VERSION ""

NS_ :

BS_:

BU_: Host Node0 Node1 Node2 Node3 Node4 Node5 Node6 Node7

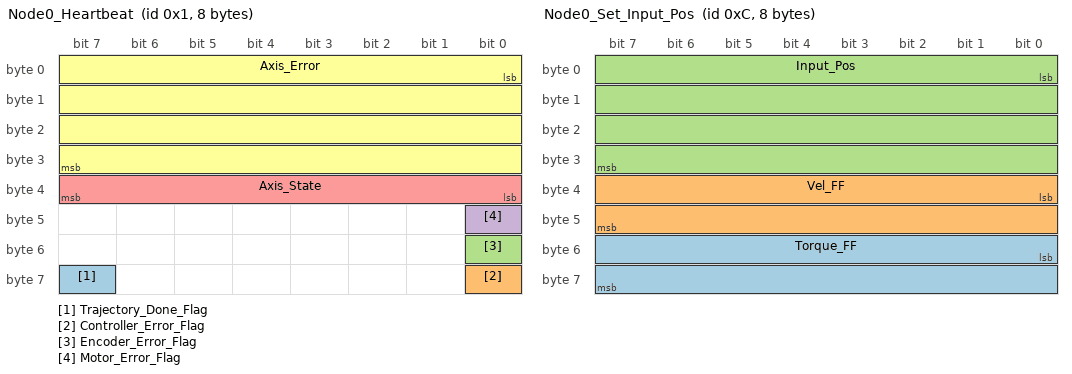
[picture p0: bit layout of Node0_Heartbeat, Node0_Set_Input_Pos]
BO_ 1 Node0_Heartbeat: 8 Node0
 SG_ Trajectory_Done_Flag : 63|1@1+ (1,0) [0|0] ""  Host
 SG_ Controller_Error_Flag : 56|1@1+ (1,0) [0|0] ""  Host
 SG_ Encoder_Error_Flag : 48|1@1+ (1,0) [0|0] ""  Host
 SG_ Motor_Error_Flag : 40|1@1+ (1,0) [0|0] ""  Host
 SG_ Axis_State : 32|8@1+ (1.0,0) [0|0] ""  Host
 SG_ Axis_Error : 0|32@1+ (1.0,0) [0|0] ""  Host

BO_ 2 Node0_Estop: 0 Host

BO_ 3 Node0_Get_Motor_Error: 8 Node0
 SG_ Motor_Error : 0|64@1+ (1.0,0) [0|0] ""  Host

BO_ 4 Node0_Get_Encoder_Error: 8 Node0
 SG_ Encoder_Error : 0|32@1+ (1.0,0) [0|0] ""  Host

BO_ 5 Node0_Get_Sensorless_Error: 8 Node0
 SG_ Sensorless_Error : 0|32@1+ (1.0,0) [0|0] ""  Host

BO_ 6 Node0_Set_Axis_Node_ID: 8 Host
 SG_ Axis_Node_ID : 0|32@1+ (1,0) [0|0] ""  Node0

BO_ 7 Node0_Set_Axis_State: 8 Host
 SG_ Axis_Requested_State : 0|32@1+ (1.0,0) [0|0] ""  Node0

BO_ 9 Node0_Get_Encoder_Estimates: 8 Node0
 SG_ Vel_Estimate : 32|32@1- (1,0) [0|0] "turn/s"  Host
 SG_ Pos_Estimate : 0|32@1- (1,0) [0|0] "turn"  Host

BO_ 10 Node0_Get_Encoder_Count: 8 Node0
 SG_ Count_In_CPR : 32|32@1- (1,0) [0|0] "counts"  Host
 SG_ Shadow_Count : 0|32@1- (1,0) [0|0] "counts"  Host

BO_ 11 Node0_Set_Controller_Mode: 8 Host
 SG_ Input_Mode : 32|32@1+ (1.0,0) [0|0] ""  Node0
 SG_ Control_Mode : 0|32@1+ (1.0,0) [0|0] ""  Node0

BO_ 12 Node0_Set_Input_Pos: 8 Host
 SG_ Torque_FF : 48|16@1- (0.001,0) [0|0] "Nm"  Node0
 SG_ Vel_FF : 32|16@1- (0.001,0) [0|0] "turn/s"  Node0
 SG_ Input_Pos : 0|32@1- (1,0) [0|0] "turn"  Node0

BO_ 13 Node0_Set_Input_Vel: 8 Host
 SG_ Input_Torque_FF : 32|32@1- (1,0) [0|0] "Nm"  Node0
 SG_ Input_Vel : 0|32@1- (1,0) [0|0] "turn/s"  Node0

BO_ 14 Node0_Set_Input_Torque: 8 Host
 SG_ Input_Torque : 0|32@1- (1,0) [0|0] "Nm"  Node0

BO_ 15 Node0_Set_Limits: 8 Host
 SG_ Current_Limit : 32|32@1- (1,0) [0|0] "A"  Node0
 SG_ Velocity_Limit : 0|32@1- (1,0) [0|0] "turn/s"  Node0

BO_ 16 Node0_Start_Anticogging: 0 Host

BO_ 17 Node0_Set_Traj_Vel_Limit: 8 Host
 SG_ Traj_Vel_Limit : 0|32@1- (1,0) [0|0] "turn/s"  Node0

BO_ 18 Node0_Set_Traj_Accel_Limits: 8 Host
 SG_ Traj_Decel_Limit : 32|32@1- (1,0) [0|0] "turn/s^2"  Node0
 SG_ Traj_Accel_Limit : 0|32@1- (1,0) [0|0] "turn/s^2"  Node0

BO_ 19 Node0_Set_Traj_Inertia: 8 Host
 SG_ Traj_Inertia : 0|32@1- (1,0) [0|0] "Nm/(turn/s^2)"  Node0

BO_ 20 Node0_Get_Iq: 8 Node0
 SG_ Iq_Measured : 32|32@1- (1,0) [0|0] "A"  Host
 SG_ Iq_Setpoint : 0|32@1- (1,0) [0|0] "A"  Host

BO_ 21 Node0_Get_Sensorless_Estimates: 8 Node0
 SG_ Sensorless_Vel_Estimate : 32|32@1- (1,0) [0|0] "turn/s"  Host
 SG_ Sensorless_Pos_Estimate : 0|32@1- (1,0) [0|0] "turn"  Host

BO_ 22 Node0_Reboot: 0 Host

BO_ 23 Node0_Get_Bus_Voltage_Current: 8 Node0
 SG_ Bus_Current : 32|32@1- (1,0) [0|0] "A"  Host
 SG_ Bus_Voltage : 0|32@1- (1,0) [0|0] "V"  Host

BO_ 24 Node0_Clear_Errors: 0 Host

BO_ 25 Node0_Set_Linear_Count: 8 Host
 SG_ Position : 0|32@1- (1,0) [0|0] "counts"  Node0

BO_ 26 Node0_Set_Pos_Gain: 8 Host
 SG_ Pos_Gain : 0|32@1- (1,0) [0|0] "(turn/s)/turn"  Node0

BO_ 27 Node0_Set_Vel_Gains: 8 Host
 SG_ Vel_Integrator_Gain : 32|32@1- (1,0) [0|0] "Nm/turn"  Node0
 SG_ Vel_Gain : 0|32@1- (1,0) [0|0] "Nm/(turn/s)"  Node0

BO_ 28 Node0_Get_ADC_Voltage: 8 Node0
 SG_ ADC_Voltage : 0|32@1- (1,0) [0|0] "V"  Host

BO_ 29 Node0_Get_Controller_Error: 8 Node0
 SG_ Controller_Error : 0|32@1+ (1.0,0) [0|0] ""  Host

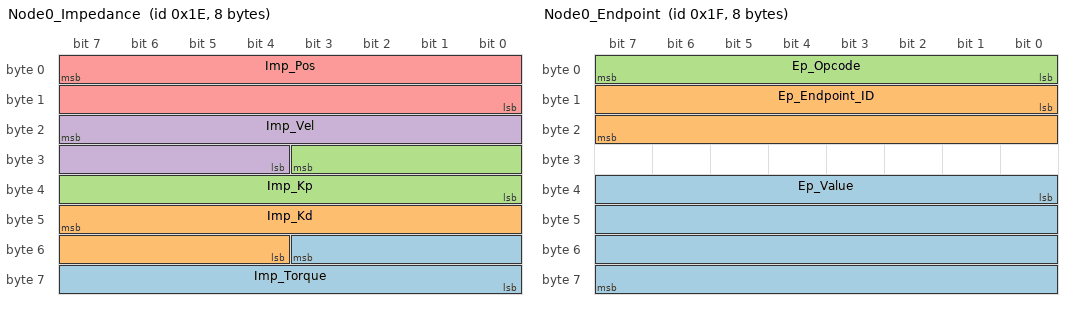
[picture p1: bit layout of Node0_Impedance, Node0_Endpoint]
BO_ 30 Node0_Impedance: 8 Host
 SG_ Imp_Torque : 51|12@0- (0.0019540791402051783,0) [0|0] "Nm"  Node0
 SG_ Imp_Kd : 47|12@0+ (0.0004884004884004884,0) [0|0] "Nm/(turn/s)"  Node0
 SG_ Imp_Kp : 27|12@0+ (0.04884004884004884,0) [0|0] "Nm/turn"  Node0
 SG_ Imp_Vel : 23|12@0- (0.015632633121641426,0) [0|0] "turn/s"  Node0
 SG_ Imp_Pos : 7|16@0- (0.0004882961516159551,0) [0|0] "turn"  Node0

BO_ 31 Node0_Endpoint: 8 Host
 SG_ Ep_Value : 32|32@1+ (1,0) [0|0] ""  Node0
 SG_ Ep_Endpoint_ID : 8|16@1+ (1,0) [0|0] ""  Node0
 SG_ Ep_Opcode : 0|8@1+ (1.0,0) [0|0] ""  Node0

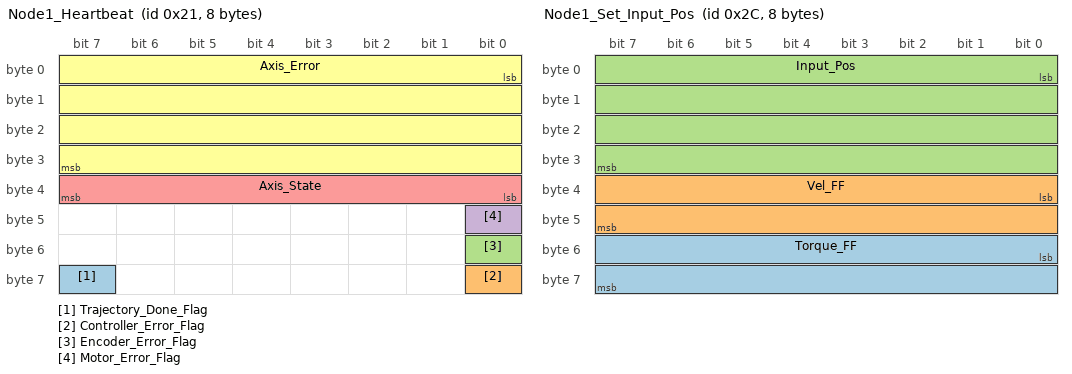
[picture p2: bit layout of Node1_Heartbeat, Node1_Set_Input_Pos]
BO_ 33 Node1_Heartbeat: 8 Node1
 SG_ Trajectory_Done_Flag : 63|1@1+ (1,0) [0|0] ""  Host
 SG_ Controller_Error_Flag : 56|1@1+ (1,0) [0|0] ""  Host
 SG_ Encoder_Error_Flag : 48|1@1+ (1,0) [0|0] ""  Host
 SG_ Motor_Error_Flag : 40|1@1+ (1,0) [0|0] ""  Host
 SG_ Axis_State : 32|8@1+ (1.0,0) [0|0] ""  Host
 SG_ Axis_Error : 0|32@1+ (1.0,0) [0|0] ""  Host

BO_ 34 Node1_Estop: 0 Host

BO_ 35 Node1_Get_Motor_Error: 8 Node1
 SG_ Motor_Error : 0|64@1+ (1.0,0) [0|0] ""  Host

BO_ 36 Node1_Get_Encoder_Error: 8 Node1
 SG_ Encoder_Error : 0|32@1+ (1.0,0) [0|0] ""  Host

BO_ 37 Node1_Get_Sensorless_Error: 8 Node1
 SG_ Sensorless_Error : 0|32@1+ (1.0,0) [0|0] ""  Host

BO_ 38 Node1_Set_Axis_Node_ID: 8 Host
 SG_ Axis_Node_ID : 0|32@1+ (1,0) [0|0] ""  Node1

BO_ 39 Node1_Set_Axis_State: 8 Host
 SG_ Axis_Requested_State : 0|32@1+ (1.0,0) [0|0] ""  Node1

BO_ 41 Node1_Get_Encoder_Estimates: 8 Node1
 SG_ Vel_Estimate : 32|32@1- (1,0) [0|0] "turn/s"  Host
 SG_ Pos_Estimate : 0|32@1- (1,0) [0|0] "turn"  Host

BO_ 42 Node1_Get_Encoder_Count: 8 Node1
 SG_ Count_In_CPR : 32|32@1- (1,0) [0|0] "counts"  Host
 SG_ Shadow_Count : 0|32@1- (1,0) [0|0] "counts"  Host

BO_ 43 Node1_Set_Controller_Mode: 8 Host
 SG_ Input_Mode : 32|32@1+ (1.0,0) [0|0] ""  Node1
 SG_ Control_Mode : 0|32@1+ (1.0,0) [0|0] ""  Node1

BO_ 44 Node1_Set_Input_Pos: 8 Host
 SG_ Torque_FF : 48|16@1- (0.001,0) [0|0] "Nm"  Node1
 SG_ Vel_FF : 32|16@1- (0.001,0) [0|0] "turn/s"  Node1
 SG_ Input_Pos : 0|32@1- (1,0) [0|0] "turn"  Node1

BO_ 45 Node1_Set_Input_Vel: 8 Host
 SG_ Input_Torque_FF : 32|32@1- (1,0) [0|0] "Nm"  Node1
 SG_ Input_Vel : 0|32@1- (1,0) [0|0] "turn/s"  Node1

BO_ 46 Node1_Set_Input_Torque: 8 Host
 SG_ Input_Torque : 0|32@1- (1,0) [0|0] "Nm"  Node1

BO_ 47 Node1_Set_Limits: 8 Host
 SG_ Current_Limit : 32|32@1- (1,0) [0|0] "A"  Node1
 SG_ Velocity_Limit : 0|32@1- (1,0) [0|0] "turn/s"  Node1

BO_ 48 Node1_Start_Anticogging: 0 Host

BO_ 49 Node1_Set_Traj_Vel_Limit: 8 Host
 SG_ Traj_Vel_Limit : 0|32@1- (1,0) [0|0] "turn/s"  Node1

BO_ 50 Node1_Set_Traj_Accel_Limits: 8 Host
 SG_ Traj_Decel_Limit : 32|32@1- (1,0) [0|0] "turn/s^2"  Node1
 SG_ Traj_Accel_Limit : 0|32@1- (1,0) [0|0] "turn/s^2"  Node1

BO_ 51 Node1_Set_Traj_Inertia: 8 Host
 SG_ Traj_Inertia : 0|32@1- (1,0) [0|0] "Nm/(turn/s^2)"  Node1

BO_ 52 Node1_Get_Iq: 8 Node1
 SG_ Iq_Measured : 32|32@1- (1,0) [0|0] "A"  Host
 SG_ Iq_Setpoint : 0|32@1- (1,0) [0|0] "A"  Host

BO_ 53 Node1_Get_Sensorless_Estimates: 8 Node1
 SG_ Sensorless_Vel_Estimate : 32|32@1- (1,0) [0|0] "turn/s"  Host
 SG_ Sensorless_Pos_Estimate : 0|32@1- (1,0) [0|0] "turn"  Host

BO_ 54 Node1_Reboot: 0 Host

BO_ 55 Node1_Get_Bus_Voltage_Current: 8 Node1
 SG_ Bus_Current : 32|32@1- (1,0) [0|0] "A"  Host
 SG_ Bus_Voltage : 0|32@1- (1,0) [0|0] "V"  Host

BO_ 56 Node1_Clear_Errors: 0 Host

BO_ 57 Node1_Set_Linear_Count: 8 Host
 SG_ Position : 0|32@1- (1,0) [0|0] "counts"  Node1

BO_ 58 Node1_Set_Pos_Gain: 8 Host
 SG_ Pos_Gain : 0|32@1- (1,0) [0|0] "(turn/s)/turn"  Node1

BO_ 59 Node1_Set_Vel_Gains: 8 Host
 SG_ Vel_Integrator_Gain : 32|32@1- (1,0) [0|0] "Nm/turn"  Node1
 SG_ Vel_Gain : 0|32@1- (1,0) [0|0] "Nm/(turn/s)"  Node1

BO_ 60 Node1_Get_ADC_Voltage: 8 Node1
 SG_ ADC_Voltage : 0|32@1- (1,0) [0|0] "V"  Host

BO_ 61 Node1_Get_Controller_Error: 8 Node1
 SG_ Controller_Error : 0|32@1+ (1.0,0) [0|0] ""  Host

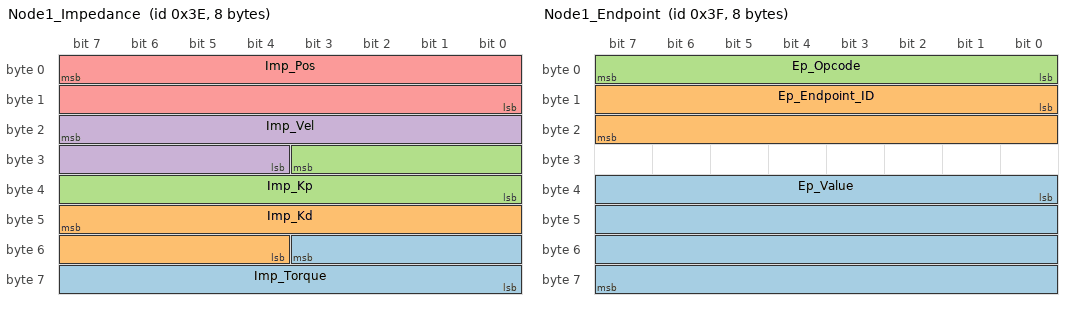
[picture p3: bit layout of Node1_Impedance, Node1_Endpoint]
BO_ 62 Node1_Impedance: 8 Host
 SG_ Imp_Torque : 51|12@0- (0.0019540791402051783,0) [0|0] "Nm"  Node1
 SG_ Imp_Kd : 47|12@0+ (0.0004884004884004884,0) [0|0] "Nm/(turn/s)"  Node1
 SG_ Imp_Kp : 27|12@0+ (0.04884004884004884,0) [0|0] "Nm/turn"  Node1
 SG_ Imp_Vel : 23|12@0- (0.015632633121641426,0) [0|0] "turn/s"  Node1
 SG_ Imp_Pos : 7|16@0- (0.0004882961516159551,0) [0|0] "turn"  Node1

BO_ 63 Node1_Endpoint: 8 Host
 SG_ Ep_Value : 32|32@1+ (1,0) [0|0] ""  Node1
 SG_ Ep_Endpoint_ID : 8|16@1+ (1,0) [0|0] ""  Node1
 SG_ Ep_Opcode : 0|8@1+ (1.0,0) [0|0] ""  Node1

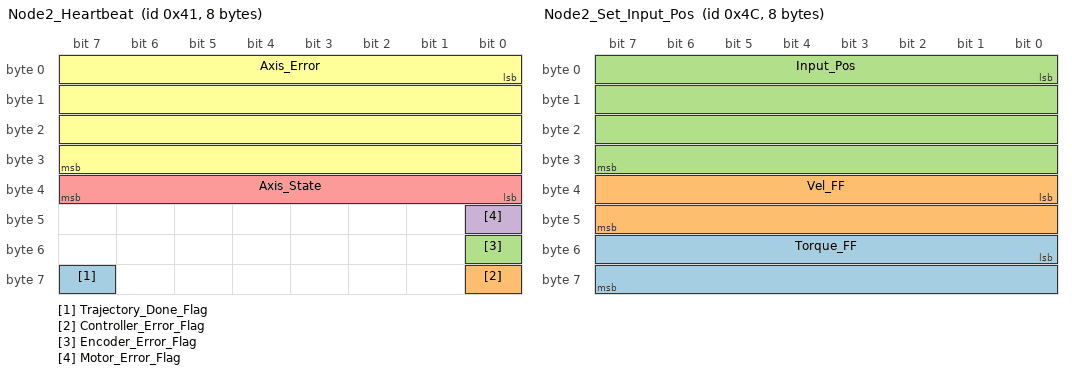
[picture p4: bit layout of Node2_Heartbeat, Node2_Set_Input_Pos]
BO_ 65 Node2_Heartbeat: 8 Node2
 SG_ Trajectory_Done_Flag : 63|1@1+ (1,0) [0|0] ""  Host
 SG_ Controller_Error_Flag : 56|1@1+ (1,0) [0|0] ""  Host
 SG_ Encoder_Error_Flag : 48|1@1+ (1,0) [0|0] ""  Host
 SG_ Motor_Error_Flag : 40|1@1+ (1,0) [0|0] ""  Host
 SG_ Axis_State : 32|8@1+ (1.0,0) [0|0] ""  Host
 SG_ Axis_Error : 0|32@1+ (1.0,0) [0|0] ""  Host

BO_ 66 Node2_Estop: 0 Host

BO_ 67 Node2_Get_Motor_Error: 8 Node2
 SG_ Motor_Error : 0|64@1+ (1.0,0) [0|0] ""  Host

BO_ 68 Node2_Get_Encoder_Error: 8 Node2
 SG_ Encoder_Error : 0|32@1+ (1.0,0) [0|0] ""  Host

BO_ 69 Node2_Get_Sensorless_Error: 8 Node2
 SG_ Sensorless_Error : 0|32@1+ (1.0,0) [0|0] ""  Host

BO_ 70 Node2_Set_Axis_Node_ID: 8 Host
 SG_ Axis_Node_ID : 0|32@1+ (1,0) [0|0] ""  Node2

BO_ 71 Node2_Set_Axis_State: 8 Host
 SG_ Axis_Requested_State : 0|32@1+ (1.0,0) [0|0] ""  Node2

BO_ 73 Node2_Get_Encoder_Estimates: 8 Node2
 SG_ Vel_Estimate : 32|32@1- (1,0) [0|0] "turn/s"  Host
 SG_ Pos_Estimate : 0|32@1- (1,0) [0|0] "turn"  Host

BO_ 74 Node2_Get_Encoder_Count: 8 Node2
 SG_ Count_In_CPR : 32|32@1- (1,0) [0|0] "counts"  Host
 SG_ Shadow_Count : 0|32@1- (1,0) [0|0] "counts"  Host

BO_ 75 Node2_Set_Controller_Mode: 8 Host
 SG_ Input_Mode : 32|32@1+ (1.0,0) [0|0] ""  Node2
 SG_ Control_Mode : 0|32@1+ (1.0,0) [0|0] ""  Node2

BO_ 76 Node2_Set_Input_Pos: 8 Host
 SG_ Torque_FF : 48|16@1- (0.001,0) [0|0] "Nm"  Node2
 SG_ Vel_FF : 32|16@1- (0.001,0) [0|0] "turn/s"  Node2
 SG_ Input_Pos : 0|32@1- (1,0) [0|0] "turn"  Node2

BO_ 77 Node2_Set_Input_Vel: 8 Host
 SG_ Input_Torque_FF : 32|32@1- (1,0) [0|0] "Nm"  Node2
 SG_ Input_Vel : 0|32@1- (1,0) [0|0] "turn/s"  Node2

BO_ 78 Node2_Set_Input_Torque: 8 Host
 SG_ Input_Torque : 0|32@1- (1,0) [0|0] "Nm"  Node2

BO_ 79 Node2_Set_Limits: 8 Host
 SG_ Current_Limit : 32|32@1- (1,0) [0|0] "A"  Node2
 SG_ Velocity_Limit : 0|32@1- (1,0) [0|0] "turn/s"  Node2

BO_ 80 Node2_Start_Anticogging: 0 Host

BO_ 81 Node2_Set_Traj_Vel_Limit: 8 Host
 SG_ Traj_Vel_Limit : 0|32@1- (1,0) [0|0] "turn/s"  Node2

BO_ 82 Node2_Set_Traj_Accel_Limits: 8 Host
 SG_ Traj_Decel_Limit : 32|32@1- (1,0) [0|0] "turn/s^2"  Node2
 SG_ Traj_Accel_Limit : 0|32@1- (1,0) [0|0] "turn/s^2"  Node2

BO_ 83 Node2_Set_Traj_Inertia: 8 Host
 SG_ Traj_Inertia : 0|32@1- (1,0) [0|0] "Nm/(turn/s^2)"  Node2

BO_ 84 Node2_Get_Iq: 8 Node2
 SG_ Iq_Measured : 32|32@1- (1,0) [0|0] "A"  Host
 SG_ Iq_Setpoint : 0|32@1- (1,0) [0|0] "A"  Host

BO_ 85 Node2_Get_Sensorless_Estimates: 8 Node2
 SG_ Sensorless_Vel_Estimate : 32|32@1- (1,0) [0|0] "turn/s"  Host
 SG_ Sensorless_Pos_Estimate : 0|32@1- (1,0) [0|0] "turn"  Host

BO_ 86 Node2_Reboot: 0 Host

BO_ 87 Node2_Get_Bus_Voltage_Current: 8 Node2
 SG_ Bus_Current : 32|32@1- (1,0) [0|0] "A"  Host
 SG_ Bus_Voltage : 0|32@1- (1,0) [0|0] "V"  Host

BO_ 88 Node2_Clear_Errors: 0 Host

BO_ 89 Node2_Set_Linear_Count: 8 Host
 SG_ Position : 0|32@1- (1,0) [0|0] "counts"  Node2

BO_ 90 Node2_Set_Pos_Gain: 8 Host
 SG_ Pos_Gain : 0|32@1- (1,0) [0|0] "(turn/s)/turn"  Node2

BO_ 91 Node2_Set_Vel_Gains: 8 Host
 SG_ Vel_Integrator_Gain : 32|32@1- (1,0) [0|0] "Nm/turn"  Node2
 SG_ Vel_Gain : 0|32@1- (1,0) [0|0] "Nm/(turn/s)"  Node2

BO_ 92 Node2_Get_ADC_Voltage: 8 Node2
 SG_ ADC_Voltage : 0|32@1- (1,0) [0|0] "V"  Host

BO_ 93 Node2_Get_Controller_Error: 8 Node2
 SG_ Controller_Error : 0|32@1+ (1.0,0) [0|0] ""  Host

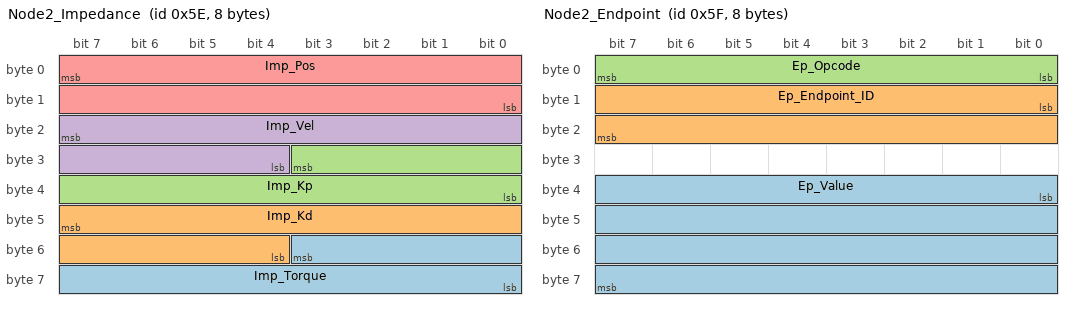
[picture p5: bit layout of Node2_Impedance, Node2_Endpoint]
BO_ 94 Node2_Impedance: 8 Host
 SG_ Imp_Torque : 51|12@0- (0.0019540791402051783,0) [0|0] "Nm"  Node2
 SG_ Imp_Kd : 47|12@0+ (0.0004884004884004884,0) [0|0] "Nm/(turn/s)"  Node2
 SG_ Imp_Kp : 27|12@0+ (0.04884004884004884,0) [0|0] "Nm/turn"  Node2
 SG_ Imp_Vel : 23|12@0- (0.015632633121641426,0) [0|0] "turn/s"  Node2
 SG_ Imp_Pos : 7|16@0- (0.0004882961516159551,0) [0|0] "turn"  Node2

BO_ 95 Node2_Endpoint: 8 Host
 SG_ Ep_Value : 32|32@1+ (1,0) [0|0] ""  Node2
 SG_ Ep_Endpoint_ID : 8|16@1+ (1,0) [0|0] ""  Node2
 SG_ Ep_Opcode : 0|8@1+ (1.0,0) [0|0] ""  Node2

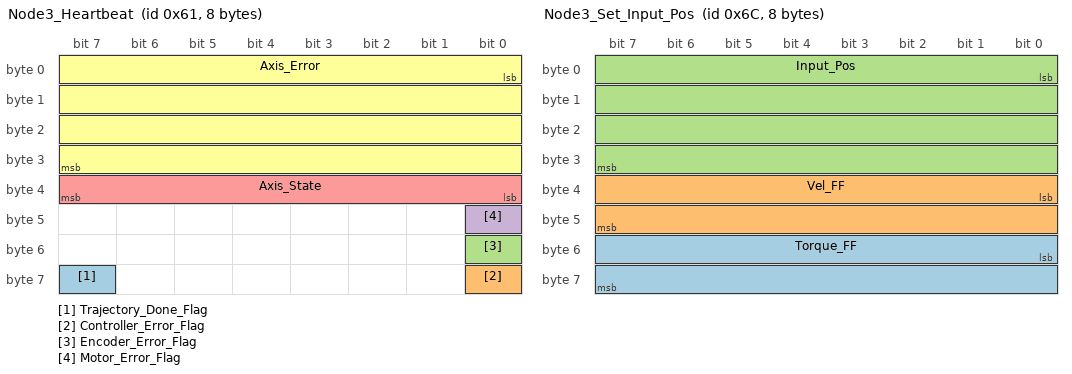
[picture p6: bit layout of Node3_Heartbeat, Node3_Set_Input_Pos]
BO_ 97 Node3_Heartbeat: 8 Node3
 SG_ Trajectory_Done_Flag : 63|1@1+ (1,0) [0|0] ""  Host
 SG_ Controller_Error_Flag : 56|1@1+ (1,0) [0|0] ""  Host
 SG_ Encoder_Error_Flag : 48|1@1+ (1,0) [0|0] ""  Host
 SG_ Motor_Error_Flag : 40|1@1+ (1,0) [0|0] ""  Host
 SG_ Axis_State : 32|8@1+ (1.0,0) [0|0] ""  Host
 SG_ Axis_Error : 0|32@1+ (1.0,0) [0|0] ""  Host

BO_ 98 Node3_Estop: 0 Host

BO_ 99 Node3_Get_Motor_Error: 8 Node3
 SG_ Motor_Error : 0|64@1+ (1.0,0) [0|0] ""  Host

BO_ 100 Node3_Get_Encoder_Error: 8 Node3
 SG_ Encoder_Error : 0|32@1+ (1.0,0) [0|0] ""  Host

BO_ 101 Node3_Get_Sensorless_Error: 8 Node3
 SG_ Sensorless_Error : 0|32@1+ (1.0,0) [0|0] ""  Host

BO_ 102 Node3_Set_Axis_Node_ID: 8 Host
 SG_ Axis_Node_ID : 0|32@1+ (1,0) [0|0] ""  Node3

BO_ 103 Node3_Set_Axis_State: 8 Host
 SG_ Axis_Requested_State : 0|32@1+ (1.0,0) [0|0] ""  Node3

BO_ 105 Node3_Get_Encoder_Estimates: 8 Node3
 SG_ Vel_Estimate : 32|32@1- (1,0) [0|0] "turn/s"  Host
 SG_ Pos_Estimate : 0|32@1- (1,0) [0|0] "turn"  Host

BO_ 106 Node3_Get_Encoder_Count: 8 Node3
 SG_ Count_In_CPR : 32|32@1- (1,0) [0|0] "counts"  Host
 SG_ Shadow_Count : 0|32@1- (1,0) [0|0] "counts"  Host

BO_ 107 Node3_Set_Controller_Mode: 8 Host
 SG_ Input_Mode : 32|32@1+ (1.0,0) [0|0] ""  Node3
 SG_ Control_Mode : 0|32@1+ (1.0,0) [0|0] ""  Node3

BO_ 108 Node3_Set_Input_Pos: 8 Host
 SG_ Torque_FF : 48|16@1- (0.001,0) [0|0] "Nm"  Node3
 SG_ Vel_FF : 32|16@1- (0.001,0) [0|0] "turn/s"  Node3
 SG_ Input_Pos : 0|32@1- (1,0) [0|0] "turn"  Node3

BO_ 109 Node3_Set_Input_Vel: 8 Host
 SG_ Input_Torque_FF : 32|32@1- (1,0) [0|0] "Nm"  Node3
 SG_ Input_Vel : 0|32@1- (1,0) [0|0] "turn/s"  Node3

BO_ 110 Node3_Set_Input_Torque: 8 Host
 SG_ Input_Torque : 0|32@1- (1,0) [0|0] "Nm"  Node3

BO_ 111 Node3_Set_Limits: 8 Host
 SG_ Current_Limit : 32|32@1- (1,0) [0|0] "A"  Node3
 SG_ Velocity_Limit : 0|32@1- (1,0) [0|0] "turn/s"  Node3

BO_ 112 Node3_Start_Anticogging: 0 Host

BO_ 113 Node3_Set_Traj_Vel_Limit: 8 Host
 SG_ Traj_Vel_Limit : 0|32@1- (1,0) [0|0] "turn/s"  Node3

BO_ 114 Node3_Set_Traj_Accel_Limits: 8 Host
 SG_ Traj_Decel_Limit : 32|32@1- (1,0) [0|0] "turn/s^2"  Node3
 SG_ Traj_Accel_Limit : 0|32@1- (1,0) [0|0] "turn/s^2"  Node3

BO_ 115 Node3_Set_Traj_Inertia: 8 Host
 SG_ Traj_Inertia : 0|32@1- (1,0) [0|0] "Nm/(turn/s^2)"  Node3

BO_ 116 Node3_Get_Iq: 8 Node3
 SG_ Iq_Measured : 32|32@1- (1,0) [0|0] "A"  Host
 SG_ Iq_Setpoint : 0|32@1- (1,0) [0|0] "A"  Host

BO_ 117 Node3_Get_Sensorless_Estimates: 8 Node3
 SG_ Sensorless_Vel_Estimate : 32|32@1- (1,0) [0|0] "turn/s"  Host
 SG_ Sensorless_Pos_Estimate : 0|32@1- (1,0) [0|0] "turn"  Host

BO_ 118 Node3_Reboot: 0 Host

BO_ 119 Node3_Get_Bus_Voltage_Current: 8 Node3
 SG_ Bus_Current : 32|32@1- (1,0) [0|0] "A"  Host
 SG_ Bus_Voltage : 0|32@1- (1,0) [0|0] "V"  Host

BO_ 120 Node3_Clear_Errors: 0 Host

BO_ 121 Node3_Set_Linear_Count: 8 Host
 SG_ Position : 0|32@1- (1,0) [0|0] "counts"  Node3

BO_ 122 Node3_Set_Pos_Gain: 8 Host
 SG_ Pos_Gain : 0|32@1- (1,0) [0|0] "(turn/s)/turn"  Node3

BO_ 123 Node3_Set_Vel_Gains: 8 Host
 SG_ Vel_Integrator_Gain : 32|32@1- (1,0) [0|0] "Nm/turn"  Node3
 SG_ Vel_Gain : 0|32@1- (1,0) [0|0] "Nm/(turn/s)"  Node3

BO_ 124 Node3_Get_ADC_Voltage: 8 Node3
 SG_ ADC_Voltage : 0|32@1- (1,0) [0|0] "V"  Host

BO_ 125 Node3_Get_Controller_Error: 8 Node3
 SG_ Controller_Error : 0|32@1+ (1.0,0) [0|0] ""  Host

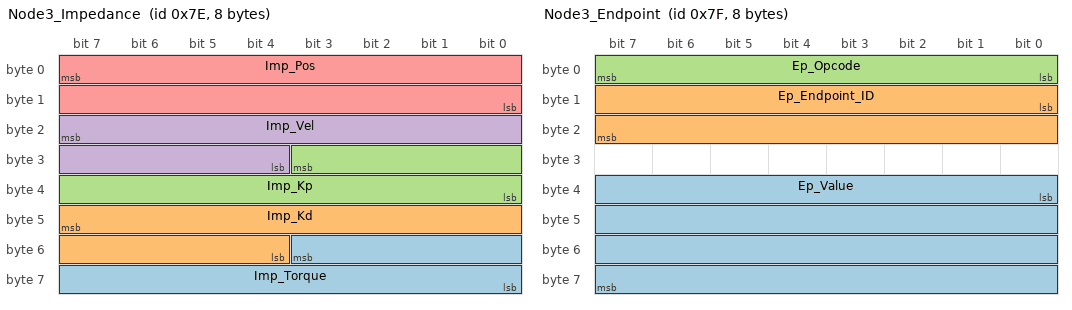
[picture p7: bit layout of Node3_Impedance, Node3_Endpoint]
BO_ 126 Node3_Impedance: 8 Host
 SG_ Imp_Torque : 51|12@0- (0.0019540791402051783,0) [0|0] "Nm"  Node3
 SG_ Imp_Kd : 47|12@0+ (0.0004884004884004884,0) [0|0] "Nm/(turn/s)"  Node3
 SG_ Imp_Kp : 27|12@0+ (0.04884004884004884,0) [0|0] "Nm/turn"  Node3
 SG_ Imp_Vel : 23|12@0- (0.015632633121641426,0) [0|0] "turn/s"  Node3
 SG_ Imp_Pos : 7|16@0- (0.0004882961516159551,0) [0|0] "turn"  Node3

BO_ 127 Node3_Endpoint: 8 Host
 SG_ Ep_Value : 32|32@1+ (1,0) [0|0] ""  Node3
 SG_ Ep_Endpoint_ID : 8|16@1+ (1,0) [0|0] ""  Node3
 SG_ Ep_Opcode : 0|8@1+ (1.0,0) [0|0] ""  Node3

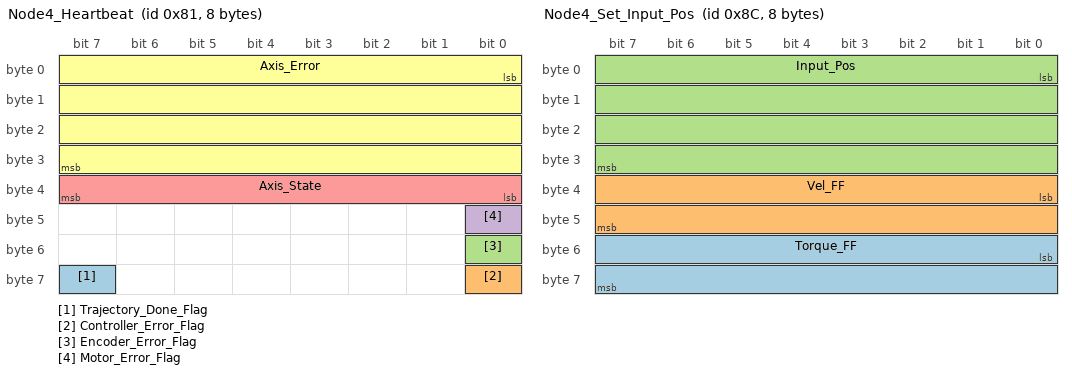
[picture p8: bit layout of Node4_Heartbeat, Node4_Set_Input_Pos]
BO_ 129 Node4_Heartbeat: 8 Node4
 SG_ Trajectory_Done_Flag : 63|1@1+ (1,0) [0|0] ""  Host
 SG_ Controller_Error_Flag : 56|1@1+ (1,0) [0|0] ""  Host
 SG_ Encoder_Error_Flag : 48|1@1+ (1,0) [0|0] ""  Host
 SG_ Motor_Error_Flag : 40|1@1+ (1,0) [0|0] ""  Host
 SG_ Axis_State : 32|8@1+ (1.0,0) [0|0] ""  Host
 SG_ Axis_Error : 0|32@1+ (1.0,0) [0|0] ""  Host

BO_ 130 Node4_Estop: 0 Host

BO_ 131 Node4_Get_Motor_Error: 8 Node4
 SG_ Motor_Error : 0|64@1+ (1.0,0) [0|0] ""  Host

BO_ 132 Node4_Get_Encoder_Error: 8 Node4
 SG_ Encoder_Error : 0|32@1+ (1.0,0) [0|0] ""  Host

BO_ 133 Node4_Get_Sensorless_Error: 8 Node4
 SG_ Sensorless_Error : 0|32@1+ (1.0,0) [0|0] ""  Host

BO_ 134 Node4_Set_Axis_Node_ID: 8 Host
 SG_ Axis_Node_ID : 0|32@1+ (1,0) [0|0] ""  Node4

BO_ 135 Node4_Set_Axis_State: 8 Host
 SG_ Axis_Requested_State : 0|32@1+ (1.0,0) [0|0] ""  Node4

BO_ 137 Node4_Get_Encoder_Estimates: 8 Node4
 SG_ Vel_Estimate : 32|32@1- (1,0) [0|0] "turn/s"  Host
 SG_ Pos_Estimate : 0|32@1- (1,0) [0|0] "turn"  Host

BO_ 138 Node4_Get_Encoder_Count: 8 Node4
 SG_ Count_In_CPR : 32|32@1- (1,0) [0|0] "counts"  Host
 SG_ Shadow_Count : 0|32@1- (1,0) [0|0] "counts"  Host

BO_ 139 Node4_Set_Controller_Mode: 8 Host
 SG_ Input_Mode : 32|32@1+ (1.0,0) [0|0] ""  Node4
 SG_ Control_Mode : 0|32@1+ (1.0,0) [0|0] ""  Node4

BO_ 140 Node4_Set_Input_Pos: 8 Host
 SG_ Torque_FF : 48|16@1- (0.001,0) [0|0] "Nm"  Node4
 SG_ Vel_FF : 32|16@1- (0.001,0) [0|0] "turn/s"  Node4
 SG_ Input_Pos : 0|32@1- (1,0) [0|0] "turn"  Node4

BO_ 141 Node4_Set_Input_Vel: 8 Host
 SG_ Input_Torque_FF : 32|32@1- (1,0) [0|0] "Nm"  Node4
 SG_ Input_Vel : 0|32@1- (1,0) [0|0] "turn/s"  Node4

BO_ 142 Node4_Set_Input_Torque: 8 Host
 SG_ Input_Torque : 0|32@1- (1,0) [0|0] "Nm"  Node4

BO_ 143 Node4_Set_Limits: 8 Host
 SG_ Current_Limit : 32|32@1- (1,0) [0|0] "A"  Node4
 SG_ Velocity_Limit : 0|32@1- (1,0) [0|0] "turn/s"  Node4

BO_ 144 Node4_Start_Anticogging: 0 Host

BO_ 145 Node4_Set_Traj_Vel_Limit: 8 Host
 SG_ Traj_Vel_Limit : 0|32@1- (1,0) [0|0] "turn/s"  Node4

BO_ 146 Node4_Set_Traj_Accel_Limits: 8 Host
 SG_ Traj_Decel_Limit : 32|32@1- (1,0) [0|0] "turn/s^2"  Node4
 SG_ Traj_Accel_Limit : 0|32@1- (1,0) [0|0] "turn/s^2"  Node4

BO_ 147 Node4_Set_Traj_Inertia: 8 Host
 SG_ Traj_Inertia : 0|32@1- (1,0) [0|0] "Nm/(turn/s^2)"  Node4

BO_ 148 Node4_Get_Iq: 8 Node4
 SG_ Iq_Measured : 32|32@1- (1,0) [0|0] "A"  Host
 SG_ Iq_Setpoint : 0|32@1- (1,0) [0|0] "A"  Host

BO_ 149 Node4_Get_Sensorless_Estimates: 8 Node4
 SG_ Sensorless_Vel_Estimate : 32|32@1- (1,0) [0|0] "turn/s"  Host
 SG_ Sensorless_Pos_Estimate : 0|32@1- (1,0) [0|0] "turn"  Host

BO_ 150 Node4_Reboot: 0 Host

BO_ 151 Node4_Get_Bus_Voltage_Current: 8 Node4
 SG_ Bus_Current : 32|32@1- (1,0) [0|0] "A"  Host
 SG_ Bus_Voltage : 0|32@1- (1,0) [0|0] "V"  Host

BO_ 152 Node4_Clear_Errors: 0 Host

BO_ 153 Node4_Set_Linear_Count: 8 Host
 SG_ Position : 0|32@1- (1,0) [0|0] "counts"  Node4

BO_ 154 Node4_Set_Pos_Gain: 8 Host
 SG_ Pos_Gain : 0|32@1- (1,0) [0|0] "(turn/s)/turn"  Node4

BO_ 155 Node4_Set_Vel_Gains: 8 Host
 SG_ Vel_Integrator_Gain : 32|32@1- (1,0) [0|0] "Nm/turn"  Node4
 SG_ Vel_Gain : 0|32@1- (1,0) [0|0] "Nm/(turn/s)"  Node4

BO_ 156 Node4_Get_ADC_Voltage: 8 Node4
 SG_ ADC_Voltage : 0|32@1- (1,0) [0|0] "V"  Host

BO_ 157 Node4_Get_Controller_Error: 8 Node4
 SG_ Controller_Error : 0|32@1+ (1.0,0) [0|0] ""  Host

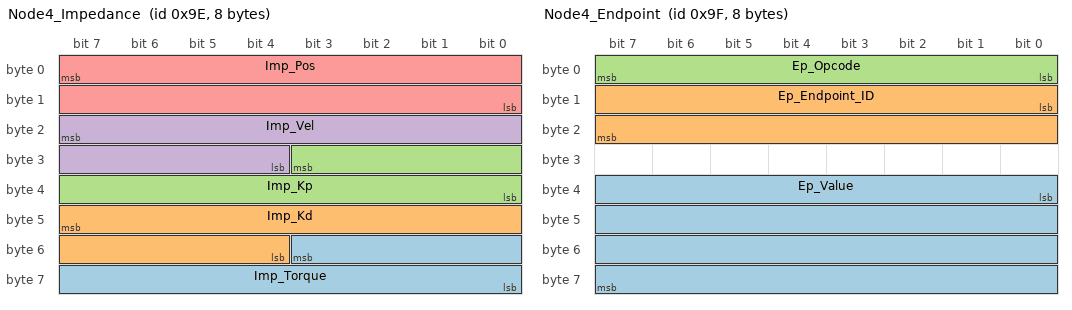
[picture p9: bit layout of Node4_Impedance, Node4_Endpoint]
BO_ 158 Node4_Impedance: 8 Host
 SG_ Imp_Torque : 51|12@0- (0.0019540791402051783,0) [0|0] "Nm"  Node4
 SG_ Imp_Kd : 47|12@0+ (0.0004884004884004884,0) [0|0] "Nm/(turn/s)"  Node4
 SG_ Imp_Kp : 27|12@0+ (0.04884004884004884,0) [0|0] "Nm/turn"  Node4
 SG_ Imp_Vel : 23|12@0- (0.015632633121641426,0) [0|0] "turn/s"  Node4
 SG_ Imp_Pos : 7|16@0- (0.0004882961516159551,0) [0|0] "turn"  Node4

BO_ 159 Node4_Endpoint: 8 Host
 SG_ Ep_Value : 32|32@1+ (1,0) [0|0] ""  Node4
 SG_ Ep_Endpoint_ID : 8|16@1+ (1,0) [0|0] ""  Node4
 SG_ Ep_Opcode : 0|8@1+ (1.0,0) [0|0] ""  Node4

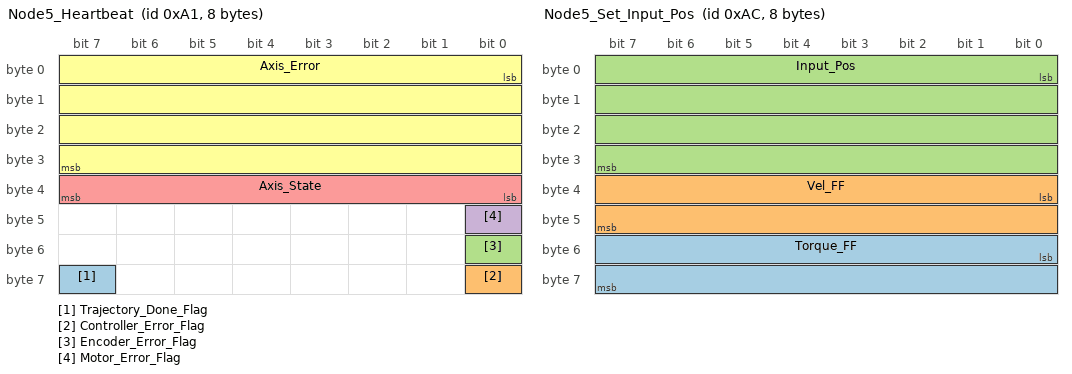
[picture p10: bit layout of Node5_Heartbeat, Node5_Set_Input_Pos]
BO_ 161 Node5_Heartbeat: 8 Node5
 SG_ Trajectory_Done_Flag : 63|1@1+ (1,0) [0|0] ""  Host
 SG_ Controller_Error_Flag : 56|1@1+ (1,0) [0|0] ""  Host
 SG_ Encoder_Error_Flag : 48|1@1+ (1,0) [0|0] ""  Host
 SG_ Motor_Error_Flag : 40|1@1+ (1,0) [0|0] ""  Host
 SG_ Axis_State : 32|8@1+ (1.0,0) [0|0] ""  Host
 SG_ Axis_Error : 0|32@1+ (1.0,0) [0|0] ""  Host

BO_ 162 Node5_Estop: 0 Host

BO_ 163 Node5_Get_Motor_Error: 8 Node5
 SG_ Motor_Error : 0|64@1+ (1.0,0) [0|0] ""  Host

BO_ 164 Node5_Get_Encoder_Error: 8 Node5
 SG_ Encoder_Error : 0|32@1+ (1.0,0) [0|0] ""  Host

BO_ 165 Node5_Get_Sensorless_Error: 8 Node5
 SG_ Sensorless_Error : 0|32@1+ (1.0,0) [0|0] ""  Host

BO_ 166 Node5_Set_Axis_Node_ID: 8 Host
 SG_ Axis_Node_ID : 0|32@1+ (1,0) [0|0] ""  Node5

BO_ 167 Node5_Set_Axis_State: 8 Host
 SG_ Axis_Requested_State : 0|32@1+ (1.0,0) [0|0] ""  Node5

BO_ 169 Node5_Get_Encoder_Estimates: 8 Node5
 SG_ Vel_Estimate : 32|32@1- (1,0) [0|0] "turn/s"  Host
 SG_ Pos_Estimate : 0|32@1- (1,0) [0|0] "turn"  Host

BO_ 170 Node5_Get_Encoder_Count: 8 Node5
 SG_ Count_In_CPR : 32|32@1- (1,0) [0|0] "counts"  Host
 SG_ Shadow_Count : 0|32@1- (1,0) [0|0] "counts"  Host

BO_ 171 Node5_Set_Controller_Mode: 8 Host
 SG_ Input_Mode : 32|32@1+ (1.0,0) [0|0] ""  Node5
 SG_ Control_Mode : 0|32@1+ (1.0,0) [0|0] ""  Node5

BO_ 172 Node5_Set_Input_Pos: 8 Host
 SG_ Torque_FF : 48|16@1- (0.001,0) [0|0] "Nm"  Node5
 SG_ Vel_FF : 32|16@1- (0.001,0) [0|0] "turn/s"  Node5
 SG_ Input_Pos : 0|32@1- (1,0) [0|0] "turn"  Node5

BO_ 173 Node5_Set_Input_Vel: 8 Host
 SG_ Input_Torque_FF : 32|32@1- (1,0) [0|0] "Nm"  Node5
 SG_ Input_Vel : 0|32@1- (1,0) [0|0] "turn/s"  Node5

BO_ 174 Node5_Set_Input_Torque: 8 Host
 SG_ Input_Torque : 0|32@1- (1,0) [0|0] "Nm"  Node5

BO_ 175 Node5_Set_Limits: 8 Host
 SG_ Current_Limit : 32|32@1- (1,0) [0|0] "A"  Node5
 SG_ Velocity_Limit : 0|32@1- (1,0) [0|0] "turn/s"  Node5

BO_ 176 Node5_Start_Anticogging: 0 Host

BO_ 177 Node5_Set_Traj_Vel_Limit: 8 Host
 SG_ Traj_Vel_Limit : 0|32@1- (1,0) [0|0] "turn/s"  Node5

BO_ 178 Node5_Set_Traj_Accel_Limits: 8 Host
 SG_ Traj_Decel_Limit : 32|32@1- (1,0) [0|0] "turn/s^2"  Node5
 SG_ Traj_Accel_Limit : 0|32@1- (1,0) [0|0] "turn/s^2"  Node5

BO_ 179 Node5_Set_Traj_Inertia: 8 Host
 SG_ Traj_Inertia : 0|32@1- (1,0) [0|0] "Nm/(turn/s^2)"  Node5

BO_ 180 Node5_Get_Iq: 8 Node5
 SG_ Iq_Measured : 32|32@1- (1,0) [0|0] "A"  Host
 SG_ Iq_Setpoint : 0|32@1- (1,0) [0|0] "A"  Host

BO_ 181 Node5_Get_Sensorless_Estimates: 8 Node5
 SG_ Sensorless_Vel_Estimate : 32|32@1- (1,0) [0|0] "turn/s"  Host
 SG_ Sensorless_Pos_Estimate : 0|32@1- (1,0) [0|0] "turn"  Host

BO_ 182 Node5_Reboot: 0 Host

BO_ 183 Node5_Get_Bus_Voltage_Current: 8 Node5
 SG_ Bus_Current : 32|32@1- (1,0) [0|0] "A"  Host
 SG_ Bus_Voltage : 0|32@1- (1,0) [0|0] "V"  Host

BO_ 184 Node5_Clear_Errors: 0 Host

BO_ 185 Node5_Set_Linear_Count: 8 Host
 SG_ Position : 0|32@1- (1,0) [0|0] "counts"  Node5

BO_ 186 Node5_Set_Pos_Gain: 8 Host
 SG_ Pos_Gain : 0|32@1- (1,0) [0|0] "(turn/s)/turn"  Node5

BO_ 187 Node5_Set_Vel_Gains: 8 Host
 SG_ Vel_Integrator_Gain : 32|32@1- (1,0) [0|0] "Nm/turn"  Node5
 SG_ Vel_Gain : 0|32@1- (1,0) [0|0] "Nm/(turn/s)"  Node5

BO_ 188 Node5_Get_ADC_Voltage: 8 Node5
 SG_ ADC_Voltage : 0|32@1- (1,0) [0|0] "V"  Host

BO_ 189 Node5_Get_Controller_Error: 8 Node5
 SG_ Controller_Error : 0|32@1+ (1.0,0) [0|0] ""  Host

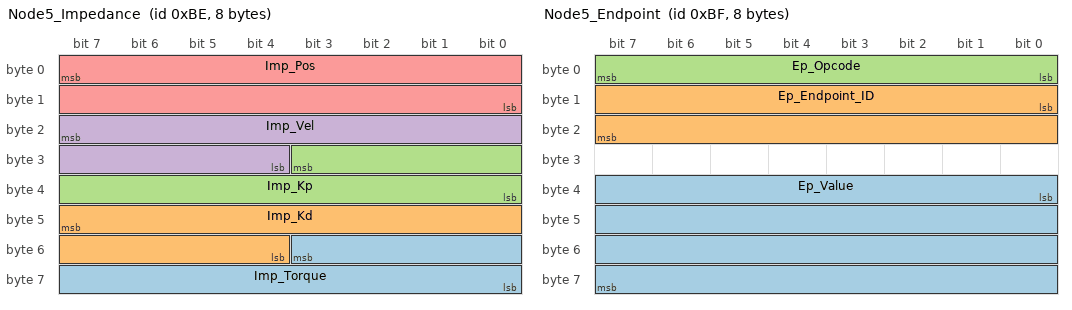
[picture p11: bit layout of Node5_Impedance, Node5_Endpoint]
BO_ 190 Node5_Impedance: 8 Host
 SG_ Imp_Torque : 51|12@0- (0.0019540791402051783,0) [0|0] "Nm"  Node5
 SG_ Imp_Kd : 47|12@0+ (0.0004884004884004884,0) [0|0] "Nm/(turn/s)"  Node5
 SG_ Imp_Kp : 27|12@0+ (0.04884004884004884,0) [0|0] "Nm/turn"  Node5
 SG_ Imp_Vel : 23|12@0- (0.015632633121641426,0) [0|0] "turn/s"  Node5
 SG_ Imp_Pos : 7|16@0- (0.0004882961516159551,0) [0|0] "turn"  Node5

BO_ 191 Node5_Endpoint: 8 Host
 SG_ Ep_Value : 32|32@1+ (1,0) [0|0] ""  Node5
 SG_ Ep_Endpoint_ID : 8|16@1+ (1,0) [0|0] ""  Node5
 SG_ Ep_Opcode : 0|8@1+ (1.0,0) [0|0] ""  Node5

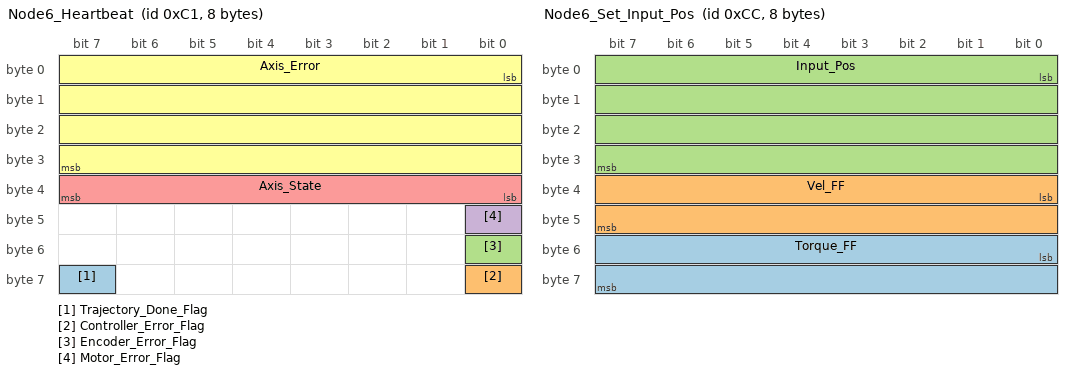
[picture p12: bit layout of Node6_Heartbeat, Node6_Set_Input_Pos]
BO_ 193 Node6_Heartbeat: 8 Node6
 SG_ Trajectory_Done_Flag : 63|1@1+ (1,0) [0|0] ""  Host
 SG_ Controller_Error_Flag : 56|1@1+ (1,0) [0|0] ""  Host
 SG_ Encoder_Error_Flag : 48|1@1+ (1,0) [0|0] ""  Host
 SG_ Motor_Error_Flag : 40|1@1+ (1,0) [0|0] ""  Host
 SG_ Axis_State : 32|8@1+ (1.0,0) [0|0] ""  Host
 SG_ Axis_Error : 0|32@1+ (1.0,0) [0|0] ""  Host

BO_ 194 Node6_Estop: 0 Host

BO_ 195 Node6_Get_Motor_Error: 8 Node6
 SG_ Motor_Error : 0|64@1+ (1.0,0) [0|0] ""  Host

BO_ 196 Node6_Get_Encoder_Error: 8 Node6
 SG_ Encoder_Error : 0|32@1+ (1.0,0) [0|0] ""  Host

BO_ 197 Node6_Get_Sensorless_Error: 8 Node6
 SG_ Sensorless_Error : 0|32@1+ (1.0,0) [0|0] ""  Host

BO_ 198 Node6_Set_Axis_Node_ID: 8 Host
 SG_ Axis_Node_ID : 0|32@1+ (1,0) [0|0] ""  Node6

BO_ 199 Node6_Set_Axis_State: 8 Host
 SG_ Axis_Requested_State : 0|32@1+ (1.0,0) [0|0] ""  Node6

BO_ 201 Node6_Get_Encoder_Estimates: 8 Node6
 SG_ Vel_Estimate : 32|32@1- (1,0) [0|0] "turn/s"  Host
 SG_ Pos_Estimate : 0|32@1- (1,0) [0|0] "turn"  Host

BO_ 202 Node6_Get_Encoder_Count: 8 Node6
 SG_ Count_In_CPR : 32|32@1- (1,0) [0|0] "counts"  Host
 SG_ Shadow_Count : 0|32@1- (1,0) [0|0] "counts"  Host

BO_ 203 Node6_Set_Controller_Mode: 8 Host
 SG_ Input_Mode : 32|32@1+ (1.0,0) [0|0] ""  Node6
 SG_ Control_Mode : 0|32@1+ (1.0,0) [0|0] ""  Node6

BO_ 204 Node6_Set_Input_Pos: 8 Host
 SG_ Torque_FF : 48|16@1- (0.001,0) [0|0] "Nm"  Node6
 SG_ Vel_FF : 32|16@1- (0.001,0) [0|0] "turn/s"  Node6
 SG_ Input_Pos : 0|32@1- (1,0) [0|0] "turn"  Node6

BO_ 205 Node6_Set_Input_Vel: 8 Host
 SG_ Input_Torque_FF : 32|32@1- (1,0) [0|0] "Nm"  Node6
 SG_ Input_Vel : 0|32@1- (1,0) [0|0] "turn/s"  Node6

BO_ 206 Node6_Set_Input_Torque: 8 Host
 SG_ Input_Torque : 0|32@1- (1,0) [0|0] "Nm"  Node6

BO_ 207 Node6_Set_Limits: 8 Host
 SG_ Current_Limit : 32|32@1- (1,0) [0|0] "A"  Node6
 SG_ Velocity_Limit : 0|32@1- (1,0) [0|0] "turn/s"  Node6

BO_ 208 Node6_Start_Anticogging: 0 Host

BO_ 209 Node6_Set_Traj_Vel_Limit: 8 Host
 SG_ Traj_Vel_Limit : 0|32@1- (1,0) [0|0] "turn/s"  Node6

BO_ 210 Node6_Set_Traj_Accel_Limits: 8 Host
 SG_ Traj_Decel_Limit : 32|32@1- (1,0) [0|0] "turn/s^2"  Node6
 SG_ Traj_Accel_Limit : 0|32@1- (1,0) [0|0] "turn/s^2"  Node6

BO_ 211 Node6_Set_Traj_Inertia: 8 Host
 SG_ Traj_Inertia : 0|32@1- (1,0) [0|0] "Nm/(turn/s^2)"  Node6

BO_ 212 Node6_Get_Iq: 8 Node6
 SG_ Iq_Measured : 32|32@1- (1,0) [0|0] "A"  Host
 SG_ Iq_Setpoint : 0|32@1- (1,0) [0|0] "A"  Host

BO_ 213 Node6_Get_Sensorless_Estimates: 8 Node6
 SG_ Sensorless_Vel_Estimate : 32|32@1- (1,0) [0|0] "turn/s"  Host
 SG_ Sensorless_Pos_Estimate : 0|32@1- (1,0) [0|0] "turn"  Host

BO_ 214 Node6_Reboot: 0 Host

BO_ 215 Node6_Get_Bus_Voltage_Current: 8 Node6
 SG_ Bus_Current : 32|32@1- (1,0) [0|0] "A"  Host
 SG_ Bus_Voltage : 0|32@1- (1,0) [0|0] "V"  Host

BO_ 216 Node6_Clear_Errors: 0 Host

BO_ 217 Node6_Set_Linear_Count: 8 Host
 SG_ Position : 0|32@1- (1,0) [0|0] "counts"  Node6

BO_ 218 Node6_Set_Pos_Gain: 8 Host
 SG_ Pos_Gain : 0|32@1- (1,0) [0|0] "(turn/s)/turn"  Node6

BO_ 219 Node6_Set_Vel_Gains: 8 Host
 SG_ Vel_Integrator_Gain : 32|32@1- (1,0) [0|0] "Nm/turn"  Node6
 SG_ Vel_Gain : 0|32@1- (1,0) [0|0] "Nm/(turn/s)"  Node6

BO_ 220 Node6_Get_ADC_Voltage: 8 Node6
 SG_ ADC_Voltage : 0|32@1- (1,0) [0|0] "V"  Host

BO_ 221 Node6_Get_Controller_Error: 8 Node6
 SG_ Controller_Error : 0|32@1+ (1.0,0) [0|0] ""  Host

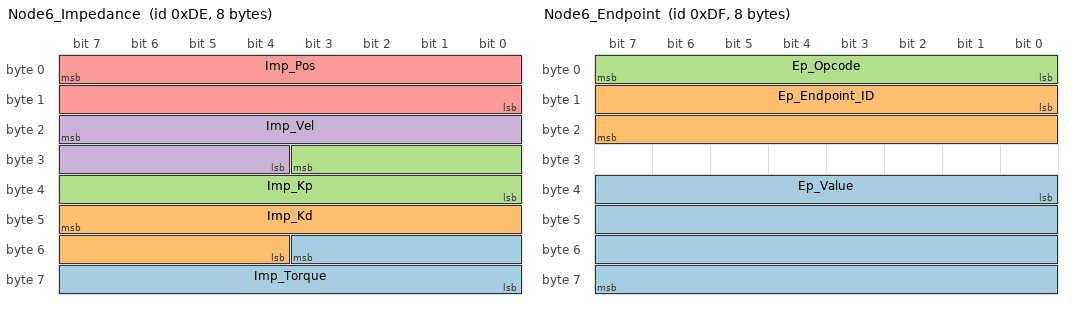
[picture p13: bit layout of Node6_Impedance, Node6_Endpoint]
BO_ 222 Node6_Impedance: 8 Host
 SG_ Imp_Torque : 51|12@0- (0.0019540791402051783,0) [0|0] "Nm"  Node6
 SG_ Imp_Kd : 47|12@0+ (0.0004884004884004884,0) [0|0] "Nm/(turn/s)"  Node6
 SG_ Imp_Kp : 27|12@0+ (0.04884004884004884,0) [0|0] "Nm/turn"  Node6
 SG_ Imp_Vel : 23|12@0- (0.015632633121641426,0) [0|0] "turn/s"  Node6
 SG_ Imp_Pos : 7|16@0- (0.0004882961516159551,0) [0|0] "turn"  Node6

BO_ 223 Node6_Endpoint: 8 Host
 SG_ Ep_Value : 32|32@1+ (1,0) [0|0] ""  Node6
 SG_ Ep_Endpoint_ID : 8|16@1+ (1,0) [0|0] ""  Node6
 SG_ Ep_Opcode : 0|8@1+ (1.0,0) [0|0] ""  Node6

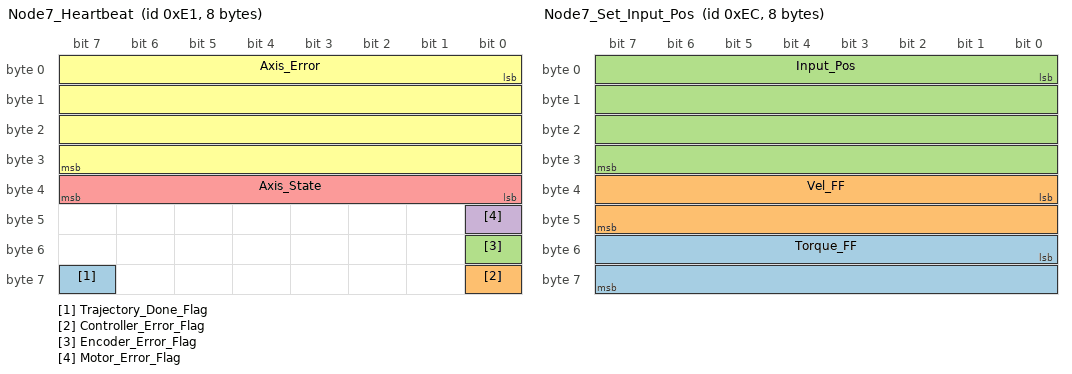
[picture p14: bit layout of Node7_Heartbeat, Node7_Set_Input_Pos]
BO_ 225 Node7_Heartbeat: 8 Node7
 SG_ Trajectory_Done_Flag : 63|1@1+ (1,0) [0|0] ""  Host
 SG_ Controller_Error_Flag : 56|1@1+ (1,0) [0|0] ""  Host
 SG_ Encoder_Error_Flag : 48|1@1+ (1,0) [0|0] ""  Host
 SG_ Motor_Error_Flag : 40|1@1+ (1,0) [0|0] ""  Host
 SG_ Axis_State : 32|8@1+ (1.0,0) [0|0] ""  Host
 SG_ Axis_Error : 0|32@1+ (1.0,0) [0|0] ""  Host

BO_ 226 Node7_Estop: 0 Host

BO_ 227 Node7_Get_Motor_Error: 8 Node7
 SG_ Motor_Error : 0|64@1+ (1.0,0) [0|0] ""  Host

BO_ 228 Node7_Get_Encoder_Error: 8 Node7
 SG_ Encoder_Error : 0|32@1+ (1.0,0) [0|0] ""  Host

BO_ 229 Node7_Get_Sensorless_Error: 8 Node7
 SG_ Sensorless_Error : 0|32@1+ (1.0,0) [0|0] ""  Host

BO_ 230 Node7_Set_Axis_Node_ID: 8 Host
 SG_ Axis_Node_ID : 0|32@1+ (1,0) [0|0] ""  Node7

BO_ 231 Node7_Set_Axis_State: 8 Host
 SG_ Axis_Requested_State : 0|32@1+ (1.0,0) [0|0] ""  Node7

BO_ 233 Node7_Get_Encoder_Estimates: 8 Node7
 SG_ Vel_Estimate : 32|32@1- (1,0) [0|0] "turn/s"  Host
 SG_ Pos_Estimate : 0|32@1- (1,0) [0|0] "turn"  Host

BO_ 234 Node7_Get_Encoder_Count: 8 Node7
 SG_ Count_In_CPR : 32|32@1- (1,0) [0|0] "counts"  Host
 SG_ Shadow_Count : 0|32@1- (1,0) [0|0] "counts"  Host

BO_ 235 Node7_Set_Controller_Mode: 8 Host
 SG_ Input_Mode : 32|32@1+ (1.0,0) [0|0] ""  Node7
 SG_ Control_Mode : 0|32@1+ (1.0,0) [0|0] ""  Node7

BO_ 236 Node7_Set_Input_Pos: 8 Host
 SG_ Torque_FF : 48|16@1- (0.001,0) [0|0] "Nm"  Node7
 SG_ Vel_FF : 32|16@1- (0.001,0) [0|0] "turn/s"  Node7
 SG_ Input_Pos : 0|32@1- (1,0) [0|0] "turn"  Node7

BO_ 237 Node7_Set_Input_Vel: 8 Host
 SG_ Input_Torque_FF : 32|32@1- (1,0) [0|0] "Nm"  Node7
 SG_ Input_Vel : 0|32@1- (1,0) [0|0] "turn/s"  Node7

BO_ 238 Node7_Set_Input_Torque: 8 Host
 SG_ Input_Torque : 0|32@1- (1,0) [0|0] "Nm"  Node7

BO_ 239 Node7_Set_Limits: 8 Host
 SG_ Current_Limit : 32|32@1- (1,0) [0|0] "A"  Node7
 SG_ Velocity_Limit : 0|32@1- (1,0) [0|0] "turn/s"  Node7

BO_ 240 Node7_Start_Anticogging: 0 Host

BO_ 241 Node7_Set_Traj_Vel_Limit: 8 Host
 SG_ Traj_Vel_Limit : 0|32@1- (1,0) [0|0] "turn/s"  Node7

BO_ 242 Node7_Set_Traj_Accel_Limits: 8 Host
 SG_ Traj_Decel_Limit : 32|32@1- (1,0) [0|0] "turn/s^2"  Node7
 SG_ Traj_Accel_Limit : 0|32@1- (1,0) [0|0] "turn/s^2"  Node7

BO_ 243 Node7_Set_Traj_Inertia: 8 Host
 SG_ Traj_Inertia : 0|32@1- (1,0) [0|0] "Nm/(turn/s^2)"  Node7

BO_ 244 Node7_Get_Iq: 8 Node7
 SG_ Iq_Measured : 32|32@1- (1,0) [0|0] "A"  Host
 SG_ Iq_Setpoint : 0|32@1- (1,0) [0|0] "A"  Host

BO_ 245 Node7_Get_Sensorless_Estimates: 8 Node7
 SG_ Sensorless_Vel_Estimate : 32|32@1- (1,0) [0|0] "turn/s"  Host
 SG_ Sensorless_Pos_Estimate : 0|32@1- (1,0) [0|0] "turn"  Host

BO_ 246 Node7_Reboot: 0 Host

BO_ 247 Node7_Get_Bus_Voltage_Current: 8 Node7
 SG_ Bus_Current : 32|32@1- (1,0) [0|0] "A"  Host
 SG_ Bus_Voltage : 0|32@1- (1,0) [0|0] "V"  Host

BO_ 248 Node7_Clear_Errors: 0 Host

BO_ 249 Node7_Set_Linear_Count: 8 Host
 SG_ Position : 0|32@1- (1,0) [0|0] "counts"  Node7

BO_ 250 Node7_Set_Pos_Gain: 8 Host
 SG_ Pos_Gain : 0|32@1- (1,0) [0|0] "(turn/s)/turn"  Node7

BO_ 251 Node7_Set_Vel_Gains: 8 Host
 SG_ Vel_Integrator_Gain : 32|32@1- (1,0) [0|0] "Nm/turn"  Node7
 SG_ Vel_Gain : 0|32@1- (1,0) [0|0] "Nm/(turn/s)"  Node7

BO_ 252 Node7_Get_ADC_Voltage: 8 Node7
 SG_ ADC_Voltage : 0|32@1- (1,0) [0|0] "V"  Host

BO_ 253 Node7_Get_Controller_Error: 8 Node7
 SG_ Controller_Error : 0|32@1+ (1.0,0) [0|0] ""  Host

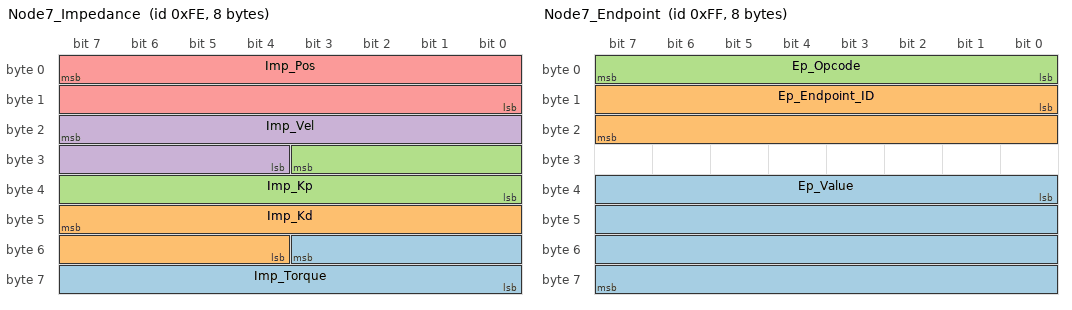
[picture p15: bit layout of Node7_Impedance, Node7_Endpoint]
BO_ 254 Node7_Impedance: 8 Host
 SG_ Imp_Torque : 51|12@0- (0.0019540791402051783,0) [0|0] "Nm"  Node7
 SG_ Imp_Kd : 47|12@0+ (0.0004884004884004884,0) [0|0] "Nm/(turn/s)"  Node7
 SG_ Imp_Kp : 27|12@0+ (0.04884004884004884,0) [0|0] "Nm/turn"  Node7
 SG_ Imp_Vel : 23|12@0- (0.015632633121641426,0) [0|0] "turn/s"  Node7
 SG_ Imp_Pos : 7|16@0- (0.0004882961516159551,0) [0|0] "turn"  Node7

BO_ 255 Node7_Endpoint: 8 Host
 SG_ Ep_Value : 32|32@1+ (1,0) [0|0] ""  Node7
 SG_ Ep_Endpoint_ID : 8|16@1+ (1,0) [0|0] ""  Node7
 SG_ Ep_Opcode : 0|8@1+ (1.0,0) [0|0] ""  Node7

CM_ BO_ 28 "Reply. The request carries the GPIO number in byte 0.";
CM_ BO_ 30 "Impedance command, with scales for the default axis.config.can.impedance_* ranges. The node answers on the same ID: pos 16 | vel 12 | torque 12 | flags 8 | FET temperature 8 (degC) | bus voltage 8 (0.25 V), big-endian; tools/xdrive/impedance_frame.py decodes it.";
CM_ BO_ 31 "Endpoint access request: read, write or call a fibre endpoint by its ID in the interface JSON, or read a buffer at a byte offset (Ep_Value). The node answers on the same ID: opcode | 0x80, endpoint ID, status (byte 3), value; tools/xdrive/endpoint_frame.py encodes and decodes both.";
CM_ BO_ 60 "Reply. The request carries the GPIO number in byte 0.";
CM_ BO_ 62 "Impedance command, with scales for the default axis.config.can.impedance_* ranges. The node answers on the same ID: pos 16 | vel 12 | torque 12 | flags 8 | FET temperature 8 (degC) | bus voltage 8 (0.25 V), big-endian; tools/xdrive/impedance_frame.py decodes it.";
CM_ BO_ 63 "Endpoint access request: read, write or call a fibre endpoint by its ID in the interface JSON, or read a buffer at a byte offset (Ep_Value). The node answers on the same ID: opcode | 0x80, endpoint ID, status (byte 3), value; tools/xdrive/endpoint_frame.py encodes and decodes both.";
CM_ BO_ 92 "Reply. The request carries the GPIO number in byte 0.";
CM_ BO_ 94 "Impedance command, with scales for the default axis.config.can.impedance_* ranges. The node answers on the same ID: pos 16 | vel 12 | torque 12 | flags 8 | FET temperature 8 (degC) | bus voltage 8 (0.25 V), big-endian; tools/xdrive/impedance_frame.py decodes it.";
CM_ BO_ 95 "Endpoint access request: read, write or call a fibre endpoint by its ID in the interface JSON, or read a buffer at a byte offset (Ep_Value). The node answers on the same ID: opcode | 0x80, endpoint ID, status (byte 3), value; tools/xdrive/endpoint_frame.py encodes and decodes both.";
CM_ BO_ 124 "Reply. The request carries the GPIO number in byte 0.";
CM_ BO_ 126 "Impedance command, with scales for the default axis.config.can.impedance_* ranges. The node answers on the same ID: pos 16 | vel 12 | torque 12 | flags 8 | FET temperature 8 (degC) | bus voltage 8 (0.25 V), big-endian; tools/xdrive/impedance_frame.py decodes it.";
CM_ BO_ 127 "Endpoint access request: read, write or call a fibre endpoint by its ID in the interface JSON, or read a buffer at a byte offset (Ep_Value). The node answers on the same ID: opcode | 0x80, endpoint ID, status (byte 3), value; tools/xdrive/endpoint_frame.py encodes and decodes both.";
CM_ BO_ 156 "Reply. The request carries the GPIO number in byte 0.";
CM_ BO_ 158 "Impedance command, with scales for the default axis.config.can.impedance_* ranges. The node answers on the same ID: pos 16 | vel 12 | torque 12 | flags 8 | FET temperature 8 (degC) | bus voltage 8 (0.25 V), big-endian; tools/xdrive/impedance_frame.py decodes it.";
CM_ BO_ 159 "Endpoint access request: read, write or call a fibre endpoint by its ID in the interface JSON, or read a buffer at a byte offset (Ep_Value). The node answers on the same ID: opcode | 0x80, endpoint ID, status (byte 3), value; tools/xdrive/endpoint_frame.py encodes and decodes both.";
CM_ BO_ 188 "Reply. The request carries the GPIO number in byte 0.";
CM_ BO_ 190 "Impedance command, with scales for the default axis.config.can.impedance_* ranges. The node answers on the same ID: pos 16 | vel 12 | torque 12 | flags 8 | FET temperature 8 (degC) | bus voltage 8 (0.25 V), big-endian; tools/xdrive/impedance_frame.py decodes it.";
CM_ BO_ 191 "Endpoint access request: read, write or call a fibre endpoint by its ID in the interface JSON, or read a buffer at a byte offset (Ep_Value). The node answers on the same ID: opcode | 0x80, endpoint ID, status (byte 3), value; tools/xdrive/endpoint_frame.py encodes and decodes both.";
CM_ BO_ 220 "Reply. The request carries the GPIO number in byte 0.";
CM_ BO_ 222 "Impedance command, with scales for the default axis.config.can.impedance_* ranges. The node answers on the same ID: pos 16 | vel 12 | torque 12 | flags 8 | FET temperature 8 (degC) | bus voltage 8 (0.25 V), big-endian; tools/xdrive/impedance_frame.py decodes it.";
CM_ BO_ 223 "Endpoint access request: read, write or call a fibre endpoint by its ID in the interface JSON, or read a buffer at a byte offset (Ep_Value). The node answers on the same ID: opcode | 0x80, endpoint ID, status (byte 3), value; tools/xdrive/endpoint_frame.py encodes and decodes both.";
CM_ BO_ 252 "Reply. The request carries the GPIO number in byte 0.";
CM_ BO_ 254 "Impedance command, with scales for the default axis.config.can.impedance_* ranges. The node answers on the same ID: pos 16 | vel 12 | torque 12 | flags 8 | FET temperature 8 (degC) | bus voltage 8 (0.25 V), big-endian; tools/xdrive/impedance_frame.py decodes it.";
CM_ BO_ 255 "Endpoint access request: read, write or call a fibre endpoint by its ID in the interface JSON, or read a buffer at a byte offset (Ep_Value). The node answers on the same ID: opcode | 0x80, endpoint ID, status (byte 3), value; tools/xdrive/endpoint_frame.py encodes and decodes both.";
BA_DEF_  "Baudrate" INT 0 10485760;
BA_DEF_DEF_  "Baudrate" 125000;
BA_ "Baudrate" 250000;
VAL_ 1 Axis_State 0 "UNDEFINED" 1 "IDLE" 2 "STARTUP_SEQUENCE" 3 "FULL_CALIBRATION_SEQUENCE" 4 "MOTOR_CALIBRATION" 6 "ENCODER_INDEX_SEARCH" 7 "ENCODER_OFFSET_CALIBRATION" 8 "CLOSED_LOOP_CONTROL" 9 "LOCKIN_SPIN" 10 "ENCODER_DIR_FIND" 11 "HOMING" 12 "ENCODER_HALL_POLARITY_CALIBRATION" 13 "ENCODER_HALL_PHASE_CALIBRATION" 14 "ENCODER_CORRECTION_CALIBRATION" ;
VAL_ 1 Axis_Error 1 "INVALID_STATE" 64 "MOTOR_FAILED" 128 "SENSORLESS_ESTIMATOR_FAILED" 256 "ENCODER_FAILED" 512 "CONTROLLER_FAILED" 2048 "WATCHDOG_TIMER_EXPIRED" 4096 "MIN_ENDSTOP_PRESSED" 8192 "MAX_ENDSTOP_PRESSED" 16384 "ESTOP_REQUESTED" 131072 "HOMING_WITHOUT_ENDSTOP" 262144 "OVER_TEMP" 524288 "UNKNOWN_POSITION" ;
VAL_ 3 Motor_Error 1 "PHASE_RESISTANCE_OUT_OF_RANGE" 2 "PHASE_INDUCTANCE_OUT_OF_RANGE" 8 "DRV_FAULT" 16 "CONTROL_DEADLINE_MISSED" 128 "MODULATION_MAGNITUDE" 1024 "CURRENT_SENSE_SATURATION" 4096 "CURRENT_LIMIT_VIOLATION" 65536 "MODULATION_IS_NAN" 131072 "MOTOR_THERMISTOR_OVER_TEMP" 262144 "FET_THERMISTOR_OVER_TEMP" 524288 "TIMER_UPDATE_MISSED" 1048576 "CURRENT_MEASUREMENT_UNAVAILABLE" 2097152 "CONTROLLER_FAILED" 4194304 "I_BUS_OUT_OF_RANGE" 8388608 "BRAKE_RESISTOR_DISARMED" 16777216 "SYSTEM_LEVEL" 33554432 "BAD_TIMING" 67108864 "UNKNOWN_PHASE_ESTIMATE" 134217728 "UNKNOWN_PHASE_VEL" 268435456 "UNKNOWN_TORQUE" 536870912 "UNKNOWN_CURRENT_COMMAND" 1073741824 "UNKNOWN_CURRENT_MEASUREMENT" 2147483648 "UNKNOWN_VBUS_VOLTAGE" 4294967296 "UNKNOWN_VOLTAGE_COMMAND" 8589934592 "UNKNOWN_GAINS" 17179869184 "CONTROLLER_INITIALIZING" 34359738368 "UNBALANCED_PHASES" ;
VAL_ 4 Encoder_Error 1 "UNSTABLE_GAIN" 2 "CPR_POLEPAIRS_MISMATCH" 4 "NO_RESPONSE" 8 "UNSUPPORTED_ENCODER_MODE" 16 "ILLEGAL_HALL_STATE" 32 "INDEX_NOT_FOUND_YET" 64 "ABS_SPI_TIMEOUT" 128 "ABS_SPI_COM_FAIL" 256 "ABS_SPI_NOT_READY" 512 "HALL_NOT_CALIBRATED_YET" ;
VAL_ 5 Sensorless_Error 1 "UNSTABLE_GAIN" 2 "UNKNOWN_CURRENT_MEASUREMENT" ;
VAL_ 7 Axis_Requested_State 0 "UNDEFINED" 1 "IDLE" 2 "STARTUP_SEQUENCE" 3 "FULL_CALIBRATION_SEQUENCE" 4 "MOTOR_CALIBRATION" 6 "ENCODER_INDEX_SEARCH" 7 "ENCODER_OFFSET_CALIBRATION" 8 "CLOSED_LOOP_CONTROL" 9 "LOCKIN_SPIN" 10 "ENCODER_DIR_FIND" 11 "HOMING" 12 "ENCODER_HALL_POLARITY_CALIBRATION" 13 "ENCODER_HALL_PHASE_CALIBRATION" 14 "ENCODER_CORRECTION_CALIBRATION" ;
VAL_ 11 Input_Mode 0 "INACTIVE" 1 "PASSTHROUGH" 2 "VEL_RAMP" 3 "POS_FILTER" 4 "MIX_CHANNELS" 5 "TRAP_TRAJ" 6 "TORQUE_RAMP" 8 "TUNING" ;
VAL_ 11 Control_Mode 0 "VOLTAGE_CONTROL" 1 "TORQUE_CONTROL" 2 "VELOCITY_CONTROL" 3 "POSITION_CONTROL" 4 "IMPEDANCE_CONTROL" ;
VAL_ 29 Controller_Error 1 "OVERSPEED" 2 "INVALID_INPUT_MODE" 4 "UNSTABLE_GAIN" 32 "INVALID_ESTIMATE" 64 "INVALID_CIRCULAR_RANGE" 128 "SPINOUT_DETECTED" 256 "POS_LIMIT_VIOLATION" 512 "POS_FOLLOWING_ERROR" 1024 "VEL_FOLLOWING_ERROR" ;
VAL_ 31 Ep_Opcode 1 "READ" 2 "WRITE" 3 "CALL" 4 "READ_BUFFER" ;
VAL_ 33 Axis_State 0 "UNDEFINED" 1 "IDLE" 2 "STARTUP_SEQUENCE" 3 "FULL_CALIBRATION_SEQUENCE" 4 "MOTOR_CALIBRATION" 6 "ENCODER_INDEX_SEARCH" 7 "ENCODER_OFFSET_CALIBRATION" 8 "CLOSED_LOOP_CONTROL" 9 "LOCKIN_SPIN" 10 "ENCODER_DIR_FIND" 11 "HOMING" 12 "ENCODER_HALL_POLARITY_CALIBRATION" 13 "ENCODER_HALL_PHASE_CALIBRATION" 14 "ENCODER_CORRECTION_CALIBRATION" ;
VAL_ 33 Axis_Error 1 "INVALID_STATE" 64 "MOTOR_FAILED" 128 "SENSORLESS_ESTIMATOR_FAILED" 256 "ENCODER_FAILED" 512 "CONTROLLER_FAILED" 2048 "WATCHDOG_TIMER_EXPIRED" 4096 "MIN_ENDSTOP_PRESSED" 8192 "MAX_ENDSTOP_PRESSED" 16384 "ESTOP_REQUESTED" 131072 "HOMING_WITHOUT_ENDSTOP" 262144 "OVER_TEMP" 524288 "UNKNOWN_POSITION" ;
VAL_ 35 Motor_Error 1 "PHASE_RESISTANCE_OUT_OF_RANGE" 2 "PHASE_INDUCTANCE_OUT_OF_RANGE" 8 "DRV_FAULT" 16 "CONTROL_DEADLINE_MISSED" 128 "MODULATION_MAGNITUDE" 1024 "CURRENT_SENSE_SATURATION" 4096 "CURRENT_LIMIT_VIOLATION" 65536 "MODULATION_IS_NAN" 131072 "MOTOR_THERMISTOR_OVER_TEMP" 262144 "FET_THERMISTOR_OVER_TEMP" 524288 "TIMER_UPDATE_MISSED" 1048576 "CURRENT_MEASUREMENT_UNAVAILABLE" 2097152 "CONTROLLER_FAILED" 4194304 "I_BUS_OUT_OF_RANGE" 8388608 "BRAKE_RESISTOR_DISARMED" 16777216 "SYSTEM_LEVEL" 33554432 "BAD_TIMING" 67108864 "UNKNOWN_PHASE_ESTIMATE" 134217728 "UNKNOWN_PHASE_VEL" 268435456 "UNKNOWN_TORQUE" 536870912 "UNKNOWN_CURRENT_COMMAND" 1073741824 "UNKNOWN_CURRENT_MEASUREMENT" 2147483648 "UNKNOWN_VBUS_VOLTAGE" 4294967296 "UNKNOWN_VOLTAGE_COMMAND" 8589934592 "UNKNOWN_GAINS" 17179869184 "CONTROLLER_INITIALIZING" 34359738368 "UNBALANCED_PHASES" ;
VAL_ 36 Encoder_Error 1 "UNSTABLE_GAIN" 2 "CPR_POLEPAIRS_MISMATCH" 4 "NO_RESPONSE" 8 "UNSUPPORTED_ENCODER_MODE" 16 "ILLEGAL_HALL_STATE" 32 "INDEX_NOT_FOUND_YET" 64 "ABS_SPI_TIMEOUT" 128 "ABS_SPI_COM_FAIL" 256 "ABS_SPI_NOT_READY" 512 "HALL_NOT_CALIBRATED_YET" ;
VAL_ 37 Sensorless_Error 1 "UNSTABLE_GAIN" 2 "UNKNOWN_CURRENT_MEASUREMENT" ;
VAL_ 39 Axis_Requested_State 0 "UNDEFINED" 1 "IDLE" 2 "STARTUP_SEQUENCE" 3 "FULL_CALIBRATION_SEQUENCE" 4 "MOTOR_CALIBRATION" 6 "ENCODER_INDEX_SEARCH" 7 "ENCODER_OFFSET_CALIBRATION" 8 "CLOSED_LOOP_CONTROL" 9 "LOCKIN_SPIN" 10 "ENCODER_DIR_FIND" 11 "HOMING" 12 "ENCODER_HALL_POLARITY_CALIBRATION" 13 "ENCODER_HALL_PHASE_CALIBRATION" 14 "ENCODER_CORRECTION_CALIBRATION" ;
VAL_ 43 Input_Mode 0 "INACTIVE" 1 "PASSTHROUGH" 2 "VEL_RAMP" 3 "POS_FILTER" 4 "MIX_CHANNELS" 5 "TRAP_TRAJ" 6 "TORQUE_RAMP" 8 "TUNING" ;
VAL_ 43 Control_Mode 0 "VOLTAGE_CONTROL" 1 "TORQUE_CONTROL" 2 "VELOCITY_CONTROL" 3 "POSITION_CONTROL" 4 "IMPEDANCE_CONTROL" ;
VAL_ 61 Controller_Error 1 "OVERSPEED" 2 "INVALID_INPUT_MODE" 4 "UNSTABLE_GAIN" 32 "INVALID_ESTIMATE" 64 "INVALID_CIRCULAR_RANGE" 128 "SPINOUT_DETECTED" 256 "POS_LIMIT_VIOLATION" 512 "POS_FOLLOWING_ERROR" 1024 "VEL_FOLLOWING_ERROR" ;
VAL_ 63 Ep_Opcode 1 "READ" 2 "WRITE" 3 "CALL" 4 "READ_BUFFER" ;
VAL_ 65 Axis_State 0 "UNDEFINED" 1 "IDLE" 2 "STARTUP_SEQUENCE" 3 "FULL_CALIBRATION_SEQUENCE" 4 "MOTOR_CALIBRATION" 6 "ENCODER_INDEX_SEARCH" 7 "ENCODER_OFFSET_CALIBRATION" 8 "CLOSED_LOOP_CONTROL" 9 "LOCKIN_SPIN" 10 "ENCODER_DIR_FIND" 11 "HOMING" 12 "ENCODER_HALL_POLARITY_CALIBRATION" 13 "ENCODER_HALL_PHASE_CALIBRATION" 14 "ENCODER_CORRECTION_CALIBRATION" ;
VAL_ 65 Axis_Error 1 "INVALID_STATE" 64 "MOTOR_FAILED" 128 "SENSORLESS_ESTIMATOR_FAILED" 256 "ENCODER_FAILED" 512 "CONTROLLER_FAILED" 2048 "WATCHDOG_TIMER_EXPIRED" 4096 "MIN_ENDSTOP_PRESSED" 8192 "MAX_ENDSTOP_PRESSED" 16384 "ESTOP_REQUESTED" 131072 "HOMING_WITHOUT_ENDSTOP" 262144 "OVER_TEMP" 524288 "UNKNOWN_POSITION" ;
VAL_ 67 Motor_Error 1 "PHASE_RESISTANCE_OUT_OF_RANGE" 2 "PHASE_INDUCTANCE_OUT_OF_RANGE" 8 "DRV_FAULT" 16 "CONTROL_DEADLINE_MISSED" 128 "MODULATION_MAGNITUDE" 1024 "CURRENT_SENSE_SATURATION" 4096 "CURRENT_LIMIT_VIOLATION" 65536 "MODULATION_IS_NAN" 131072 "MOTOR_THERMISTOR_OVER_TEMP" 262144 "FET_THERMISTOR_OVER_TEMP" 524288 "TIMER_UPDATE_MISSED" 1048576 "CURRENT_MEASUREMENT_UNAVAILABLE" 2097152 "CONTROLLER_FAILED" 4194304 "I_BUS_OUT_OF_RANGE" 8388608 "BRAKE_RESISTOR_DISARMED" 16777216 "SYSTEM_LEVEL" 33554432 "BAD_TIMING" 67108864 "UNKNOWN_PHASE_ESTIMATE" 134217728 "UNKNOWN_PHASE_VEL" 268435456 "UNKNOWN_TORQUE" 536870912 "UNKNOWN_CURRENT_COMMAND" 1073741824 "UNKNOWN_CURRENT_MEASUREMENT" 2147483648 "UNKNOWN_VBUS_VOLTAGE" 4294967296 "UNKNOWN_VOLTAGE_COMMAND" 8589934592 "UNKNOWN_GAINS" 17179869184 "CONTROLLER_INITIALIZING" 34359738368 "UNBALANCED_PHASES" ;
VAL_ 68 Encoder_Error 1 "UNSTABLE_GAIN" 2 "CPR_POLEPAIRS_MISMATCH" 4 "NO_RESPONSE" 8 "UNSUPPORTED_ENCODER_MODE" 16 "ILLEGAL_HALL_STATE" 32 "INDEX_NOT_FOUND_YET" 64 "ABS_SPI_TIMEOUT" 128 "ABS_SPI_COM_FAIL" 256 "ABS_SPI_NOT_READY" 512 "HALL_NOT_CALIBRATED_YET" ;
VAL_ 69 Sensorless_Error 1 "UNSTABLE_GAIN" 2 "UNKNOWN_CURRENT_MEASUREMENT" ;
VAL_ 71 Axis_Requested_State 0 "UNDEFINED" 1 "IDLE" 2 "STARTUP_SEQUENCE" 3 "FULL_CALIBRATION_SEQUENCE" 4 "MOTOR_CALIBRATION" 6 "ENCODER_INDEX_SEARCH" 7 "ENCODER_OFFSET_CALIBRATION" 8 "CLOSED_LOOP_CONTROL" 9 "LOCKIN_SPIN" 10 "ENCODER_DIR_FIND" 11 "HOMING" 12 "ENCODER_HALL_POLARITY_CALIBRATION" 13 "ENCODER_HALL_PHASE_CALIBRATION" 14 "ENCODER_CORRECTION_CALIBRATION" ;
VAL_ 75 Input_Mode 0 "INACTIVE" 1 "PASSTHROUGH" 2 "VEL_RAMP" 3 "POS_FILTER" 4 "MIX_CHANNELS" 5 "TRAP_TRAJ" 6 "TORQUE_RAMP" 8 "TUNING" ;
VAL_ 75 Control_Mode 0 "VOLTAGE_CONTROL" 1 "TORQUE_CONTROL" 2 "VELOCITY_CONTROL" 3 "POSITION_CONTROL" 4 "IMPEDANCE_CONTROL" ;
VAL_ 93 Controller_Error 1 "OVERSPEED" 2 "INVALID_INPUT_MODE" 4 "UNSTABLE_GAIN" 32 "INVALID_ESTIMATE" 64 "INVALID_CIRCULAR_RANGE" 128 "SPINOUT_DETECTED" 256 "POS_LIMIT_VIOLATION" 512 "POS_FOLLOWING_ERROR" 1024 "VEL_FOLLOWING_ERROR" ;
VAL_ 95 Ep_Opcode 1 "READ" 2 "WRITE" 3 "CALL" 4 "READ_BUFFER" ;
VAL_ 97 Axis_State 0 "UNDEFINED" 1 "IDLE" 2 "STARTUP_SEQUENCE" 3 "FULL_CALIBRATION_SEQUENCE" 4 "MOTOR_CALIBRATION" 6 "ENCODER_INDEX_SEARCH" 7 "ENCODER_OFFSET_CALIBRATION" 8 "CLOSED_LOOP_CONTROL" 9 "LOCKIN_SPIN" 10 "ENCODER_DIR_FIND" 11 "HOMING" 12 "ENCODER_HALL_POLARITY_CALIBRATION" 13 "ENCODER_HALL_PHASE_CALIBRATION" 14 "ENCODER_CORRECTION_CALIBRATION" ;
VAL_ 97 Axis_Error 1 "INVALID_STATE" 64 "MOTOR_FAILED" 128 "SENSORLESS_ESTIMATOR_FAILED" 256 "ENCODER_FAILED" 512 "CONTROLLER_FAILED" 2048 "WATCHDOG_TIMER_EXPIRED" 4096 "MIN_ENDSTOP_PRESSED" 8192 "MAX_ENDSTOP_PRESSED" 16384 "ESTOP_REQUESTED" 131072 "HOMING_WITHOUT_ENDSTOP" 262144 "OVER_TEMP" 524288 "UNKNOWN_POSITION" ;
VAL_ 99 Motor_Error 1 "PHASE_RESISTANCE_OUT_OF_RANGE" 2 "PHASE_INDUCTANCE_OUT_OF_RANGE" 8 "DRV_FAULT" 16 "CONTROL_DEADLINE_MISSED" 128 "MODULATION_MAGNITUDE" 1024 "CURRENT_SENSE_SATURATION" 4096 "CURRENT_LIMIT_VIOLATION" 65536 "MODULATION_IS_NAN" 131072 "MOTOR_THERMISTOR_OVER_TEMP" 262144 "FET_THERMISTOR_OVER_TEMP" 524288 "TIMER_UPDATE_MISSED" 1048576 "CURRENT_MEASUREMENT_UNAVAILABLE" 2097152 "CONTROLLER_FAILED" 4194304 "I_BUS_OUT_OF_RANGE" 8388608 "BRAKE_RESISTOR_DISARMED" 16777216 "SYSTEM_LEVEL" 33554432 "BAD_TIMING" 67108864 "UNKNOWN_PHASE_ESTIMATE" 134217728 "UNKNOWN_PHASE_VEL" 268435456 "UNKNOWN_TORQUE" 536870912 "UNKNOWN_CURRENT_COMMAND" 1073741824 "UNKNOWN_CURRENT_MEASUREMENT" 2147483648 "UNKNOWN_VBUS_VOLTAGE" 4294967296 "UNKNOWN_VOLTAGE_COMMAND" 8589934592 "UNKNOWN_GAINS" 17179869184 "CONTROLLER_INITIALIZING" 34359738368 "UNBALANCED_PHASES" ;
VAL_ 100 Encoder_Error 1 "UNSTABLE_GAIN" 2 "CPR_POLEPAIRS_MISMATCH" 4 "NO_RESPONSE" 8 "UNSUPPORTED_ENCODER_MODE" 16 "ILLEGAL_HALL_STATE" 32 "INDEX_NOT_FOUND_YET" 64 "ABS_SPI_TIMEOUT" 128 "ABS_SPI_COM_FAIL" 256 "ABS_SPI_NOT_READY" 512 "HALL_NOT_CALIBRATED_YET" ;
VAL_ 101 Sensorless_Error 1 "UNSTABLE_GAIN" 2 "UNKNOWN_CURRENT_MEASUREMENT" ;
VAL_ 103 Axis_Requested_State 0 "UNDEFINED" 1 "IDLE" 2 "STARTUP_SEQUENCE" 3 "FULL_CALIBRATION_SEQUENCE" 4 "MOTOR_CALIBRATION" 6 "ENCODER_INDEX_SEARCH" 7 "ENCODER_OFFSET_CALIBRATION" 8 "CLOSED_LOOP_CONTROL" 9 "LOCKIN_SPIN" 10 "ENCODER_DIR_FIND" 11 "HOMING" 12 "ENCODER_HALL_POLARITY_CALIBRATION" 13 "ENCODER_HALL_PHASE_CALIBRATION" 14 "ENCODER_CORRECTION_CALIBRATION" ;
VAL_ 107 Input_Mode 0 "INACTIVE" 1 "PASSTHROUGH" 2 "VEL_RAMP" 3 "POS_FILTER" 4 "MIX_CHANNELS" 5 "TRAP_TRAJ" 6 "TORQUE_RAMP" 8 "TUNING" ;
VAL_ 107 Control_Mode 0 "VOLTAGE_CONTROL" 1 "TORQUE_CONTROL" 2 "VELOCITY_CONTROL" 3 "POSITION_CONTROL" 4 "IMPEDANCE_CONTROL" ;
VAL_ 125 Controller_Error 1 "OVERSPEED" 2 "INVALID_INPUT_MODE" 4 "UNSTABLE_GAIN" 32 "INVALID_ESTIMATE" 64 "INVALID_CIRCULAR_RANGE" 128 "SPINOUT_DETECTED" 256 "POS_LIMIT_VIOLATION" 512 "POS_FOLLOWING_ERROR" 1024 "VEL_FOLLOWING_ERROR" ;
VAL_ 127 Ep_Opcode 1 "READ" 2 "WRITE" 3 "CALL" 4 "READ_BUFFER" ;
VAL_ 129 Axis_State 0 "UNDEFINED" 1 "IDLE" 2 "STARTUP_SEQUENCE" 3 "FULL_CALIBRATION_SEQUENCE" 4 "MOTOR_CALIBRATION" 6 "ENCODER_INDEX_SEARCH" 7 "ENCODER_OFFSET_CALIBRATION" 8 "CLOSED_LOOP_CONTROL" 9 "LOCKIN_SPIN" 10 "ENCODER_DIR_FIND" 11 "HOMING" 12 "ENCODER_HALL_POLARITY_CALIBRATION" 13 "ENCODER_HALL_PHASE_CALIBRATION" 14 "ENCODER_CORRECTION_CALIBRATION" ;
VAL_ 129 Axis_Error 1 "INVALID_STATE" 64 "MOTOR_FAILED" 128 "SENSORLESS_ESTIMATOR_FAILED" 256 "ENCODER_FAILED" 512 "CONTROLLER_FAILED" 2048 "WATCHDOG_TIMER_EXPIRED" 4096 "MIN_ENDSTOP_PRESSED" 8192 "MAX_ENDSTOP_PRESSED" 16384 "ESTOP_REQUESTED" 131072 "HOMING_WITHOUT_ENDSTOP" 262144 "OVER_TEMP" 524288 "UNKNOWN_POSITION" ;
VAL_ 131 Motor_Error 1 "PHASE_RESISTANCE_OUT_OF_RANGE" 2 "PHASE_INDUCTANCE_OUT_OF_RANGE" 8 "DRV_FAULT" 16 "CONTROL_DEADLINE_MISSED" 128 "MODULATION_MAGNITUDE" 1024 "CURRENT_SENSE_SATURATION" 4096 "CURRENT_LIMIT_VIOLATION" 65536 "MODULATION_IS_NAN" 131072 "MOTOR_THERMISTOR_OVER_TEMP" 262144 "FET_THERMISTOR_OVER_TEMP" 524288 "TIMER_UPDATE_MISSED" 1048576 "CURRENT_MEASUREMENT_UNAVAILABLE" 2097152 "CONTROLLER_FAILED" 4194304 "I_BUS_OUT_OF_RANGE" 8388608 "BRAKE_RESISTOR_DISARMED" 16777216 "SYSTEM_LEVEL" 33554432 "BAD_TIMING" 67108864 "UNKNOWN_PHASE_ESTIMATE" 134217728 "UNKNOWN_PHASE_VEL" 268435456 "UNKNOWN_TORQUE" 536870912 "UNKNOWN_CURRENT_COMMAND" 1073741824 "UNKNOWN_CURRENT_MEASUREMENT" 2147483648 "UNKNOWN_VBUS_VOLTAGE" 4294967296 "UNKNOWN_VOLTAGE_COMMAND" 8589934592 "UNKNOWN_GAINS" 17179869184 "CONTROLLER_INITIALIZING" 34359738368 "UNBALANCED_PHASES" ;
VAL_ 132 Encoder_Error 1 "UNSTABLE_GAIN" 2 "CPR_POLEPAIRS_MISMATCH" 4 "NO_RESPONSE" 8 "UNSUPPORTED_ENCODER_MODE" 16 "ILLEGAL_HALL_STATE" 32 "INDEX_NOT_FOUND_YET" 64 "ABS_SPI_TIMEOUT" 128 "ABS_SPI_COM_FAIL" 256 "ABS_SPI_NOT_READY" 512 "HALL_NOT_CALIBRATED_YET" ;
VAL_ 133 Sensorless_Error 1 "UNSTABLE_GAIN" 2 "UNKNOWN_CURRENT_MEASUREMENT" ;
VAL_ 135 Axis_Requested_State 0 "UNDEFINED" 1 "IDLE" 2 "STARTUP_SEQUENCE" 3 "FULL_CALIBRATION_SEQUENCE" 4 "MOTOR_CALIBRATION" 6 "ENCODER_INDEX_SEARCH" 7 "ENCODER_OFFSET_CALIBRATION" 8 "CLOSED_LOOP_CONTROL" 9 "LOCKIN_SPIN" 10 "ENCODER_DIR_FIND" 11 "HOMING" 12 "ENCODER_HALL_POLARITY_CALIBRATION" 13 "ENCODER_HALL_PHASE_CALIBRATION" 14 "ENCODER_CORRECTION_CALIBRATION" ;
VAL_ 139 Input_Mode 0 "INACTIVE" 1 "PASSTHROUGH" 2 "VEL_RAMP" 3 "POS_FILTER" 4 "MIX_CHANNELS" 5 "TRAP_TRAJ" 6 "TORQUE_RAMP" 8 "TUNING" ;
VAL_ 139 Control_Mode 0 "VOLTAGE_CONTROL" 1 "TORQUE_CONTROL" 2 "VELOCITY_CONTROL" 3 "POSITION_CONTROL" 4 "IMPEDANCE_CONTROL" ;
VAL_ 157 Controller_Error 1 "OVERSPEED" 2 "INVALID_INPUT_MODE" 4 "UNSTABLE_GAIN" 32 "INVALID_ESTIMATE" 64 "INVALID_CIRCULAR_RANGE" 128 "SPINOUT_DETECTED" 256 "POS_LIMIT_VIOLATION" 512 "POS_FOLLOWING_ERROR" 1024 "VEL_FOLLOWING_ERROR" ;
VAL_ 159 Ep_Opcode 1 "READ" 2 "WRITE" 3 "CALL" 4 "READ_BUFFER" ;
VAL_ 161 Axis_State 0 "UNDEFINED" 1 "IDLE" 2 "STARTUP_SEQUENCE" 3 "FULL_CALIBRATION_SEQUENCE" 4 "MOTOR_CALIBRATION" 6 "ENCODER_INDEX_SEARCH" 7 "ENCODER_OFFSET_CALIBRATION" 8 "CLOSED_LOOP_CONTROL" 9 "LOCKIN_SPIN" 10 "ENCODER_DIR_FIND" 11 "HOMING" 12 "ENCODER_HALL_POLARITY_CALIBRATION" 13 "ENCODER_HALL_PHASE_CALIBRATION" 14 "ENCODER_CORRECTION_CALIBRATION" ;
VAL_ 161 Axis_Error 1 "INVALID_STATE" 64 "MOTOR_FAILED" 128 "SENSORLESS_ESTIMATOR_FAILED" 256 "ENCODER_FAILED" 512 "CONTROLLER_FAILED" 2048 "WATCHDOG_TIMER_EXPIRED" 4096 "MIN_ENDSTOP_PRESSED" 8192 "MAX_ENDSTOP_PRESSED" 16384 "ESTOP_REQUESTED" 131072 "HOMING_WITHOUT_ENDSTOP" 262144 "OVER_TEMP" 524288 "UNKNOWN_POSITION" ;
VAL_ 163 Motor_Error 1 "PHASE_RESISTANCE_OUT_OF_RANGE" 2 "PHASE_INDUCTANCE_OUT_OF_RANGE" 8 "DRV_FAULT" 16 "CONTROL_DEADLINE_MISSED" 128 "MODULATION_MAGNITUDE" 1024 "CURRENT_SENSE_SATURATION" 4096 "CURRENT_LIMIT_VIOLATION" 65536 "MODULATION_IS_NAN" 131072 "MOTOR_THERMISTOR_OVER_TEMP" 262144 "FET_THERMISTOR_OVER_TEMP" 524288 "TIMER_UPDATE_MISSED" 1048576 "CURRENT_MEASUREMENT_UNAVAILABLE" 2097152 "CONTROLLER_FAILED" 4194304 "I_BUS_OUT_OF_RANGE" 8388608 "BRAKE_RESISTOR_DISARMED" 16777216 "SYSTEM_LEVEL" 33554432 "BAD_TIMING" 67108864 "UNKNOWN_PHASE_ESTIMATE" 134217728 "UNKNOWN_PHASE_VEL" 268435456 "UNKNOWN_TORQUE" 536870912 "UNKNOWN_CURRENT_COMMAND" 1073741824 "UNKNOWN_CURRENT_MEASUREMENT" 2147483648 "UNKNOWN_VBUS_VOLTAGE" 4294967296 "UNKNOWN_VOLTAGE_COMMAND" 8589934592 "UNKNOWN_GAINS" 17179869184 "CONTROLLER_INITIALIZING" 34359738368 "UNBALANCED_PHASES" ;
VAL_ 164 Encoder_Error 1 "UNSTABLE_GAIN" 2 "CPR_POLEPAIRS_MISMATCH" 4 "NO_RESPONSE" 8 "UNSUPPORTED_ENCODER_MODE" 16 "ILLEGAL_HALL_STATE" 32 "INDEX_NOT_FOUND_YET" 64 "ABS_SPI_TIMEOUT" 128 "ABS_SPI_COM_FAIL" 256 "ABS_SPI_NOT_READY" 512 "HALL_NOT_CALIBRATED_YET" ;
VAL_ 165 Sensorless_Error 1 "UNSTABLE_GAIN" 2 "UNKNOWN_CURRENT_MEASUREMENT" ;
VAL_ 167 Axis_Requested_State 0 "UNDEFINED" 1 "IDLE" 2 "STARTUP_SEQUENCE" 3 "FULL_CALIBRATION_SEQUENCE" 4 "MOTOR_CALIBRATION" 6 "ENCODER_INDEX_SEARCH" 7 "ENCODER_OFFSET_CALIBRATION" 8 "CLOSED_LOOP_CONTROL" 9 "LOCKIN_SPIN" 10 "ENCODER_DIR_FIND" 11 "HOMING" 12 "ENCODER_HALL_POLARITY_CALIBRATION" 13 "ENCODER_HALL_PHASE_CALIBRATION" 14 "ENCODER_CORRECTION_CALIBRATION" ;
VAL_ 171 Input_Mode 0 "INACTIVE" 1 "PASSTHROUGH" 2 "VEL_RAMP" 3 "POS_FILTER" 4 "MIX_CHANNELS" 5 "TRAP_TRAJ" 6 "TORQUE_RAMP" 8 "TUNING" ;
VAL_ 171 Control_Mode 0 "VOLTAGE_CONTROL" 1 "TORQUE_CONTROL" 2 "VELOCITY_CONTROL" 3 "POSITION_CONTROL" 4 "IMPEDANCE_CONTROL" ;
VAL_ 189 Controller_Error 1 "OVERSPEED" 2 "INVALID_INPUT_MODE" 4 "UNSTABLE_GAIN" 32 "INVALID_ESTIMATE" 64 "INVALID_CIRCULAR_RANGE" 128 "SPINOUT_DETECTED" 256 "POS_LIMIT_VIOLATION" 512 "POS_FOLLOWING_ERROR" 1024 "VEL_FOLLOWING_ERROR" ;
VAL_ 191 Ep_Opcode 1 "READ" 2 "WRITE" 3 "CALL" 4 "READ_BUFFER" ;
VAL_ 193 Axis_State 0 "UNDEFINED" 1 "IDLE" 2 "STARTUP_SEQUENCE" 3 "FULL_CALIBRATION_SEQUENCE" 4 "MOTOR_CALIBRATION" 6 "ENCODER_INDEX_SEARCH" 7 "ENCODER_OFFSET_CALIBRATION" 8 "CLOSED_LOOP_CONTROL" 9 "LOCKIN_SPIN" 10 "ENCODER_DIR_FIND" 11 "HOMING" 12 "ENCODER_HALL_POLARITY_CALIBRATION" 13 "ENCODER_HALL_PHASE_CALIBRATION" 14 "ENCODER_CORRECTION_CALIBRATION" ;
VAL_ 193 Axis_Error 1 "INVALID_STATE" 64 "MOTOR_FAILED" 128 "SENSORLESS_ESTIMATOR_FAILED" 256 "ENCODER_FAILED" 512 "CONTROLLER_FAILED" 2048 "WATCHDOG_TIMER_EXPIRED" 4096 "MIN_ENDSTOP_PRESSED" 8192 "MAX_ENDSTOP_PRESSED" 16384 "ESTOP_REQUESTED" 131072 "HOMING_WITHOUT_ENDSTOP" 262144 "OVER_TEMP" 524288 "UNKNOWN_POSITION" ;
VAL_ 195 Motor_Error 1 "PHASE_RESISTANCE_OUT_OF_RANGE" 2 "PHASE_INDUCTANCE_OUT_OF_RANGE" 8 "DRV_FAULT" 16 "CONTROL_DEADLINE_MISSED" 128 "MODULATION_MAGNITUDE" 1024 "CURRENT_SENSE_SATURATION" 4096 "CURRENT_LIMIT_VIOLATION" 65536 "MODULATION_IS_NAN" 131072 "MOTOR_THERMISTOR_OVER_TEMP" 262144 "FET_THERMISTOR_OVER_TEMP" 524288 "TIMER_UPDATE_MISSED" 1048576 "CURRENT_MEASUREMENT_UNAVAILABLE" 2097152 "CONTROLLER_FAILED" 4194304 "I_BUS_OUT_OF_RANGE" 8388608 "BRAKE_RESISTOR_DISARMED" 16777216 "SYSTEM_LEVEL" 33554432 "BAD_TIMING" 67108864 "UNKNOWN_PHASE_ESTIMATE" 134217728 "UNKNOWN_PHASE_VEL" 268435456 "UNKNOWN_TORQUE" 536870912 "UNKNOWN_CURRENT_COMMAND" 1073741824 "UNKNOWN_CURRENT_MEASUREMENT" 2147483648 "UNKNOWN_VBUS_VOLTAGE" 4294967296 "UNKNOWN_VOLTAGE_COMMAND" 8589934592 "UNKNOWN_GAINS" 17179869184 "CONTROLLER_INITIALIZING" 34359738368 "UNBALANCED_PHASES" ;
VAL_ 196 Encoder_Error 1 "UNSTABLE_GAIN" 2 "CPR_POLEPAIRS_MISMATCH" 4 "NO_RESPONSE" 8 "UNSUPPORTED_ENCODER_MODE" 16 "ILLEGAL_HALL_STATE" 32 "INDEX_NOT_FOUND_YET" 64 "ABS_SPI_TIMEOUT" 128 "ABS_SPI_COM_FAIL" 256 "ABS_SPI_NOT_READY" 512 "HALL_NOT_CALIBRATED_YET" ;
VAL_ 197 Sensorless_Error 1 "UNSTABLE_GAIN" 2 "UNKNOWN_CURRENT_MEASUREMENT" ;
VAL_ 199 Axis_Requested_State 0 "UNDEFINED" 1 "IDLE" 2 "STARTUP_SEQUENCE" 3 "FULL_CALIBRATION_SEQUENCE" 4 "MOTOR_CALIBRATION" 6 "ENCODER_INDEX_SEARCH" 7 "ENCODER_OFFSET_CALIBRATION" 8 "CLOSED_LOOP_CONTROL" 9 "LOCKIN_SPIN" 10 "ENCODER_DIR_FIND" 11 "HOMING" 12 "ENCODER_HALL_POLARITY_CALIBRATION" 13 "ENCODER_HALL_PHASE_CALIBRATION" 14 "ENCODER_CORRECTION_CALIBRATION" ;
VAL_ 203 Input_Mode 0 "INACTIVE" 1 "PASSTHROUGH" 2 "VEL_RAMP" 3 "POS_FILTER" 4 "MIX_CHANNELS" 5 "TRAP_TRAJ" 6 "TORQUE_RAMP" 8 "TUNING" ;
VAL_ 203 Control_Mode 0 "VOLTAGE_CONTROL" 1 "TORQUE_CONTROL" 2 "VELOCITY_CONTROL" 3 "POSITION_CONTROL" 4 "IMPEDANCE_CONTROL" ;
VAL_ 221 Controller_Error 1 "OVERSPEED" 2 "INVALID_INPUT_MODE" 4 "UNSTABLE_GAIN" 32 "INVALID_ESTIMATE" 64 "INVALID_CIRCULAR_RANGE" 128 "SPINOUT_DETECTED" 256 "POS_LIMIT_VIOLATION" 512 "POS_FOLLOWING_ERROR" 1024 "VEL_FOLLOWING_ERROR" ;
VAL_ 223 Ep_Opcode 1 "READ" 2 "WRITE" 3 "CALL" 4 "READ_BUFFER" ;
VAL_ 225 Axis_State 0 "UNDEFINED" 1 "IDLE" 2 "STARTUP_SEQUENCE" 3 "FULL_CALIBRATION_SEQUENCE" 4 "MOTOR_CALIBRATION" 6 "ENCODER_INDEX_SEARCH" 7 "ENCODER_OFFSET_CALIBRATION" 8 "CLOSED_LOOP_CONTROL" 9 "LOCKIN_SPIN" 10 "ENCODER_DIR_FIND" 11 "HOMING" 12 "ENCODER_HALL_POLARITY_CALIBRATION" 13 "ENCODER_HALL_PHASE_CALIBRATION" 14 "ENCODER_CORRECTION_CALIBRATION" ;
VAL_ 225 Axis_Error 1 "INVALID_STATE" 64 "MOTOR_FAILED" 128 "SENSORLESS_ESTIMATOR_FAILED" 256 "ENCODER_FAILED" 512 "CONTROLLER_FAILED" 2048 "WATCHDOG_TIMER_EXPIRED" 4096 "MIN_ENDSTOP_PRESSED" 8192 "MAX_ENDSTOP_PRESSED" 16384 "ESTOP_REQUESTED" 131072 "HOMING_WITHOUT_ENDSTOP" 262144 "OVER_TEMP" 524288 "UNKNOWN_POSITION" ;
VAL_ 227 Motor_Error 1 "PHASE_RESISTANCE_OUT_OF_RANGE" 2 "PHASE_INDUCTANCE_OUT_OF_RANGE" 8 "DRV_FAULT" 16 "CONTROL_DEADLINE_MISSED" 128 "MODULATION_MAGNITUDE" 1024 "CURRENT_SENSE_SATURATION" 4096 "CURRENT_LIMIT_VIOLATION" 65536 "MODULATION_IS_NAN" 131072 "MOTOR_THERMISTOR_OVER_TEMP" 262144 "FET_THERMISTOR_OVER_TEMP" 524288 "TIMER_UPDATE_MISSED" 1048576 "CURRENT_MEASUREMENT_UNAVAILABLE" 2097152 "CONTROLLER_FAILED" 4194304 "I_BUS_OUT_OF_RANGE" 8388608 "BRAKE_RESISTOR_DISARMED" 16777216 "SYSTEM_LEVEL" 33554432 "BAD_TIMING" 67108864 "UNKNOWN_PHASE_ESTIMATE" 134217728 "UNKNOWN_PHASE_VEL" 268435456 "UNKNOWN_TORQUE" 536870912 "UNKNOWN_CURRENT_COMMAND" 1073741824 "UNKNOWN_CURRENT_MEASUREMENT" 2147483648 "UNKNOWN_VBUS_VOLTAGE" 4294967296 "UNKNOWN_VOLTAGE_COMMAND" 8589934592 "UNKNOWN_GAINS" 17179869184 "CONTROLLER_INITIALIZING" 34359738368 "UNBALANCED_PHASES" ;
VAL_ 228 Encoder_Error 1 "UNSTABLE_GAIN" 2 "CPR_POLEPAIRS_MISMATCH" 4 "NO_RESPONSE" 8 "UNSUPPORTED_ENCODER_MODE" 16 "ILLEGAL_HALL_STATE" 32 "INDEX_NOT_FOUND_YET" 64 "ABS_SPI_TIMEOUT" 128 "ABS_SPI_COM_FAIL" 256 "ABS_SPI_NOT_READY" 512 "HALL_NOT_CALIBRATED_YET" ;
VAL_ 229 Sensorless_Error 1 "UNSTABLE_GAIN" 2 "UNKNOWN_CURRENT_MEASUREMENT" ;
VAL_ 231 Axis_Requested_State 0 "UNDEFINED" 1 "IDLE" 2 "STARTUP_SEQUENCE" 3 "FULL_CALIBRATION_SEQUENCE" 4 "MOTOR_CALIBRATION" 6 "ENCODER_INDEX_SEARCH" 7 "ENCODER_OFFSET_CALIBRATION" 8 "CLOSED_LOOP_CONTROL" 9 "LOCKIN_SPIN" 10 "ENCODER_DIR_FIND" 11 "HOMING" 12 "ENCODER_HALL_POLARITY_CALIBRATION" 13 "ENCODER_HALL_PHASE_CALIBRATION" 14 "ENCODER_CORRECTION_CALIBRATION" ;
VAL_ 235 Input_Mode 0 "INACTIVE" 1 "PASSTHROUGH" 2 "VEL_RAMP" 3 "POS_FILTER" 4 "MIX_CHANNELS" 5 "TRAP_TRAJ" 6 "TORQUE_RAMP" 8 "TUNING" ;
VAL_ 235 Control_Mode 0 "VOLTAGE_CONTROL" 1 "TORQUE_CONTROL" 2 "VELOCITY_CONTROL" 3 "POSITION_CONTROL" 4 "IMPEDANCE_CONTROL" ;
VAL_ 253 Controller_Error 1 "OVERSPEED" 2 "INVALID_INPUT_MODE" 4 "UNSTABLE_GAIN" 32 "INVALID_ESTIMATE" 64 "INVALID_CIRCULAR_RANGE" 128 "SPINOUT_DETECTED" 256 "POS_LIMIT_VIOLATION" 512 "POS_FOLLOWING_ERROR" 1024 "VEL_FOLLOWING_ERROR" ;
VAL_ 255 Ep_Opcode 1 "READ" 2 "WRITE" 3 "CALL" 4 "READ_BUFFER" ;
SIG_VALTYPE_ 9 Pos_Estimate : 1;
SIG_VALTYPE_ 9 Vel_Estimate : 1;
SIG_VALTYPE_ 12 Input_Pos : 1;
SIG_VALTYPE_ 13 Input_Vel : 1;
SIG_VALTYPE_ 13 Input_Torque_FF : 1;
SIG_VALTYPE_ 14 Input_Torque : 1;
SIG_VALTYPE_ 15 Velocity_Limit : 1;
SIG_VALTYPE_ 15 Current_Limit : 1;
SIG_VALTYPE_ 17 Traj_Vel_Limit : 1;
SIG_VALTYPE_ 18 Traj_Accel_Limit : 1;
SIG_VALTYPE_ 18 Traj_Decel_Limit : 1;
SIG_VALTYPE_ 19 Traj_Inertia : 1;
SIG_VALTYPE_ 20 Iq_Setpoint : 1;
SIG_VALTYPE_ 20 Iq_Measured : 1;
SIG_VALTYPE_ 21 Sensorless_Pos_Estimate : 1;
SIG_VALTYPE_ 21 Sensorless_Vel_Estimate : 1;
SIG_VALTYPE_ 23 Bus_Voltage : 1;
SIG_VALTYPE_ 23 Bus_Current : 1;
SIG_VALTYPE_ 26 Pos_Gain : 1;
SIG_VALTYPE_ 27 Vel_Gain : 1;
SIG_VALTYPE_ 27 Vel_Integrator_Gain : 1;
SIG_VALTYPE_ 28 ADC_Voltage : 1;
SIG_VALTYPE_ 41 Pos_Estimate : 1;
SIG_VALTYPE_ 41 Vel_Estimate : 1;
SIG_VALTYPE_ 44 Input_Pos : 1;
SIG_VALTYPE_ 45 Input_Vel : 1;
SIG_VALTYPE_ 45 Input_Torque_FF : 1;
SIG_VALTYPE_ 46 Input_Torque : 1;
SIG_VALTYPE_ 47 Velocity_Limit : 1;
SIG_VALTYPE_ 47 Current_Limit : 1;
SIG_VALTYPE_ 49 Traj_Vel_Limit : 1;
SIG_VALTYPE_ 50 Traj_Accel_Limit : 1;
SIG_VALTYPE_ 50 Traj_Decel_Limit : 1;
SIG_VALTYPE_ 51 Traj_Inertia : 1;
SIG_VALTYPE_ 52 Iq_Setpoint : 1;
SIG_VALTYPE_ 52 Iq_Measured : 1;
SIG_VALTYPE_ 53 Sensorless_Pos_Estimate : 1;
SIG_VALTYPE_ 53 Sensorless_Vel_Estimate : 1;
SIG_VALTYPE_ 55 Bus_Voltage : 1;
SIG_VALTYPE_ 55 Bus_Current : 1;
SIG_VALTYPE_ 58 Pos_Gain : 1;
SIG_VALTYPE_ 59 Vel_Gain : 1;
SIG_VALTYPE_ 59 Vel_Integrator_Gain : 1;
SIG_VALTYPE_ 60 ADC_Voltage : 1;
SIG_VALTYPE_ 73 Pos_Estimate : 1;
SIG_VALTYPE_ 73 Vel_Estimate : 1;
SIG_VALTYPE_ 76 Input_Pos : 1;
SIG_VALTYPE_ 77 Input_Vel : 1;
SIG_VALTYPE_ 77 Input_Torque_FF : 1;
SIG_VALTYPE_ 78 Input_Torque : 1;
SIG_VALTYPE_ 79 Velocity_Limit : 1;
SIG_VALTYPE_ 79 Current_Limit : 1;
SIG_VALTYPE_ 81 Traj_Vel_Limit : 1;
SIG_VALTYPE_ 82 Traj_Accel_Limit : 1;
SIG_VALTYPE_ 82 Traj_Decel_Limit : 1;
SIG_VALTYPE_ 83 Traj_Inertia : 1;
SIG_VALTYPE_ 84 Iq_Setpoint : 1;
SIG_VALTYPE_ 84 Iq_Measured : 1;
SIG_VALTYPE_ 85 Sensorless_Pos_Estimate : 1;
SIG_VALTYPE_ 85 Sensorless_Vel_Estimate : 1;
SIG_VALTYPE_ 87 Bus_Voltage : 1;
SIG_VALTYPE_ 87 Bus_Current : 1;
SIG_VALTYPE_ 90 Pos_Gain : 1;
SIG_VALTYPE_ 91 Vel_Gain : 1;
SIG_VALTYPE_ 91 Vel_Integrator_Gain : 1;
SIG_VALTYPE_ 92 ADC_Voltage : 1;
SIG_VALTYPE_ 105 Pos_Estimate : 1;
SIG_VALTYPE_ 105 Vel_Estimate : 1;
SIG_VALTYPE_ 108 Input_Pos : 1;
SIG_VALTYPE_ 109 Input_Vel : 1;
SIG_VALTYPE_ 109 Input_Torque_FF : 1;
SIG_VALTYPE_ 110 Input_Torque : 1;
SIG_VALTYPE_ 111 Velocity_Limit : 1;
SIG_VALTYPE_ 111 Current_Limit : 1;
SIG_VALTYPE_ 113 Traj_Vel_Limit : 1;
SIG_VALTYPE_ 114 Traj_Accel_Limit : 1;
SIG_VALTYPE_ 114 Traj_Decel_Limit : 1;
SIG_VALTYPE_ 115 Traj_Inertia : 1;
SIG_VALTYPE_ 116 Iq_Setpoint : 1;
SIG_VALTYPE_ 116 Iq_Measured : 1;
SIG_VALTYPE_ 117 Sensorless_Pos_Estimate : 1;
SIG_VALTYPE_ 117 Sensorless_Vel_Estimate : 1;
SIG_VALTYPE_ 119 Bus_Voltage : 1;
SIG_VALTYPE_ 119 Bus_Current : 1;
SIG_VALTYPE_ 122 Pos_Gain : 1;
SIG_VALTYPE_ 123 Vel_Gain : 1;
SIG_VALTYPE_ 123 Vel_Integrator_Gain : 1;
SIG_VALTYPE_ 124 ADC_Voltage : 1;
SIG_VALTYPE_ 137 Pos_Estimate : 1;
SIG_VALTYPE_ 137 Vel_Estimate : 1;
SIG_VALTYPE_ 140 Input_Pos : 1;
SIG_VALTYPE_ 141 Input_Vel : 1;
SIG_VALTYPE_ 141 Input_Torque_FF : 1;
SIG_VALTYPE_ 142 Input_Torque : 1;
SIG_VALTYPE_ 143 Velocity_Limit : 1;
SIG_VALTYPE_ 143 Current_Limit : 1;
SIG_VALTYPE_ 145 Traj_Vel_Limit : 1;
SIG_VALTYPE_ 146 Traj_Accel_Limit : 1;
SIG_VALTYPE_ 146 Traj_Decel_Limit : 1;
SIG_VALTYPE_ 147 Traj_Inertia : 1;
SIG_VALTYPE_ 148 Iq_Setpoint : 1;
SIG_VALTYPE_ 148 Iq_Measured : 1;
SIG_VALTYPE_ 149 Sensorless_Pos_Estimate : 1;
SIG_VALTYPE_ 149 Sensorless_Vel_Estimate : 1;
SIG_VALTYPE_ 151 Bus_Voltage : 1;
SIG_VALTYPE_ 151 Bus_Current : 1;
SIG_VALTYPE_ 154 Pos_Gain : 1;
SIG_VALTYPE_ 155 Vel_Gain : 1;
SIG_VALTYPE_ 155 Vel_Integrator_Gain : 1;
SIG_VALTYPE_ 156 ADC_Voltage : 1;
SIG_VALTYPE_ 169 Pos_Estimate : 1;
SIG_VALTYPE_ 169 Vel_Estimate : 1;
SIG_VALTYPE_ 172 Input_Pos : 1;
SIG_VALTYPE_ 173 Input_Vel : 1;
SIG_VALTYPE_ 173 Input_Torque_FF : 1;
SIG_VALTYPE_ 174 Input_Torque : 1;
SIG_VALTYPE_ 175 Velocity_Limit : 1;
SIG_VALTYPE_ 175 Current_Limit : 1;
SIG_VALTYPE_ 177 Traj_Vel_Limit : 1;
SIG_VALTYPE_ 178 Traj_Accel_Limit : 1;
SIG_VALTYPE_ 178 Traj_Decel_Limit : 1;
SIG_VALTYPE_ 179 Traj_Inertia : 1;
SIG_VALTYPE_ 180 Iq_Setpoint : 1;
SIG_VALTYPE_ 180 Iq_Measured : 1;
SIG_VALTYPE_ 181 Sensorless_Pos_Estimate : 1;
SIG_VALTYPE_ 181 Sensorless_Vel_Estimate : 1;
SIG_VALTYPE_ 183 Bus_Voltage : 1;
SIG_VALTYPE_ 183 Bus_Current : 1;
SIG_VALTYPE_ 186 Pos_Gain : 1;
SIG_VALTYPE_ 187 Vel_Gain : 1;
SIG_VALTYPE_ 187 Vel_Integrator_Gain : 1;
SIG_VALTYPE_ 188 ADC_Voltage : 1;
SIG_VALTYPE_ 201 Pos_Estimate : 1;
SIG_VALTYPE_ 201 Vel_Estimate : 1;
SIG_VALTYPE_ 204 Input_Pos : 1;
SIG_VALTYPE_ 205 Input_Vel : 1;
SIG_VALTYPE_ 205 Input_Torque_FF : 1;
SIG_VALTYPE_ 206 Input_Torque : 1;
SIG_VALTYPE_ 207 Velocity_Limit : 1;
SIG_VALTYPE_ 207 Current_Limit : 1;
SIG_VALTYPE_ 209 Traj_Vel_Limit : 1;
SIG_VALTYPE_ 210 Traj_Accel_Limit : 1;
SIG_VALTYPE_ 210 Traj_Decel_Limit : 1;
SIG_VALTYPE_ 211 Traj_Inertia : 1;
SIG_VALTYPE_ 212 Iq_Setpoint : 1;
SIG_VALTYPE_ 212 Iq_Measured : 1;
SIG_VALTYPE_ 213 Sensorless_Pos_Estimate : 1;
SIG_VALTYPE_ 213 Sensorless_Vel_Estimate : 1;
SIG_VALTYPE_ 215 Bus_Voltage : 1;
SIG_VALTYPE_ 215 Bus_Current : 1;
SIG_VALTYPE_ 218 Pos_Gain : 1;
SIG_VALTYPE_ 219 Vel_Gain : 1;
SIG_VALTYPE_ 219 Vel_Integrator_Gain : 1;
SIG_VALTYPE_ 220 ADC_Voltage : 1;
SIG_VALTYPE_ 233 Pos_Estimate : 1;
SIG_VALTYPE_ 233 Vel_Estimate : 1;
SIG_VALTYPE_ 236 Input_Pos : 1;
SIG_VALTYPE_ 237 Input_Vel : 1;
SIG_VALTYPE_ 237 Input_Torque_FF : 1;
SIG_VALTYPE_ 238 Input_Torque : 1;
SIG_VALTYPE_ 239 Velocity_Limit : 1;
SIG_VALTYPE_ 239 Current_Limit : 1;
SIG_VALTYPE_ 241 Traj_Vel_Limit : 1;
SIG_VALTYPE_ 242 Traj_Accel_Limit : 1;
SIG_VALTYPE_ 242 Traj_Decel_Limit : 1;
SIG_VALTYPE_ 243 Traj_Inertia : 1;
SIG_VALTYPE_ 244 Iq_Setpoint : 1;
SIG_VALTYPE_ 244 Iq_Measured : 1;
SIG_VALTYPE_ 245 Sensorless_Pos_Estimate : 1;
SIG_VALTYPE_ 245 Sensorless_Vel_Estimate : 1;
SIG_VALTYPE_ 247 Bus_Voltage : 1;
SIG_VALTYPE_ 247 Bus_Current : 1;
SIG_VALTYPE_ 250 Pos_Gain : 1;
SIG_VALTYPE_ 251 Vel_Gain : 1;
SIG_VALTYPE_ 251 Vel_Integrator_Gain : 1;
SIG_VALTYPE_ 252 ADC_Voltage : 1;
